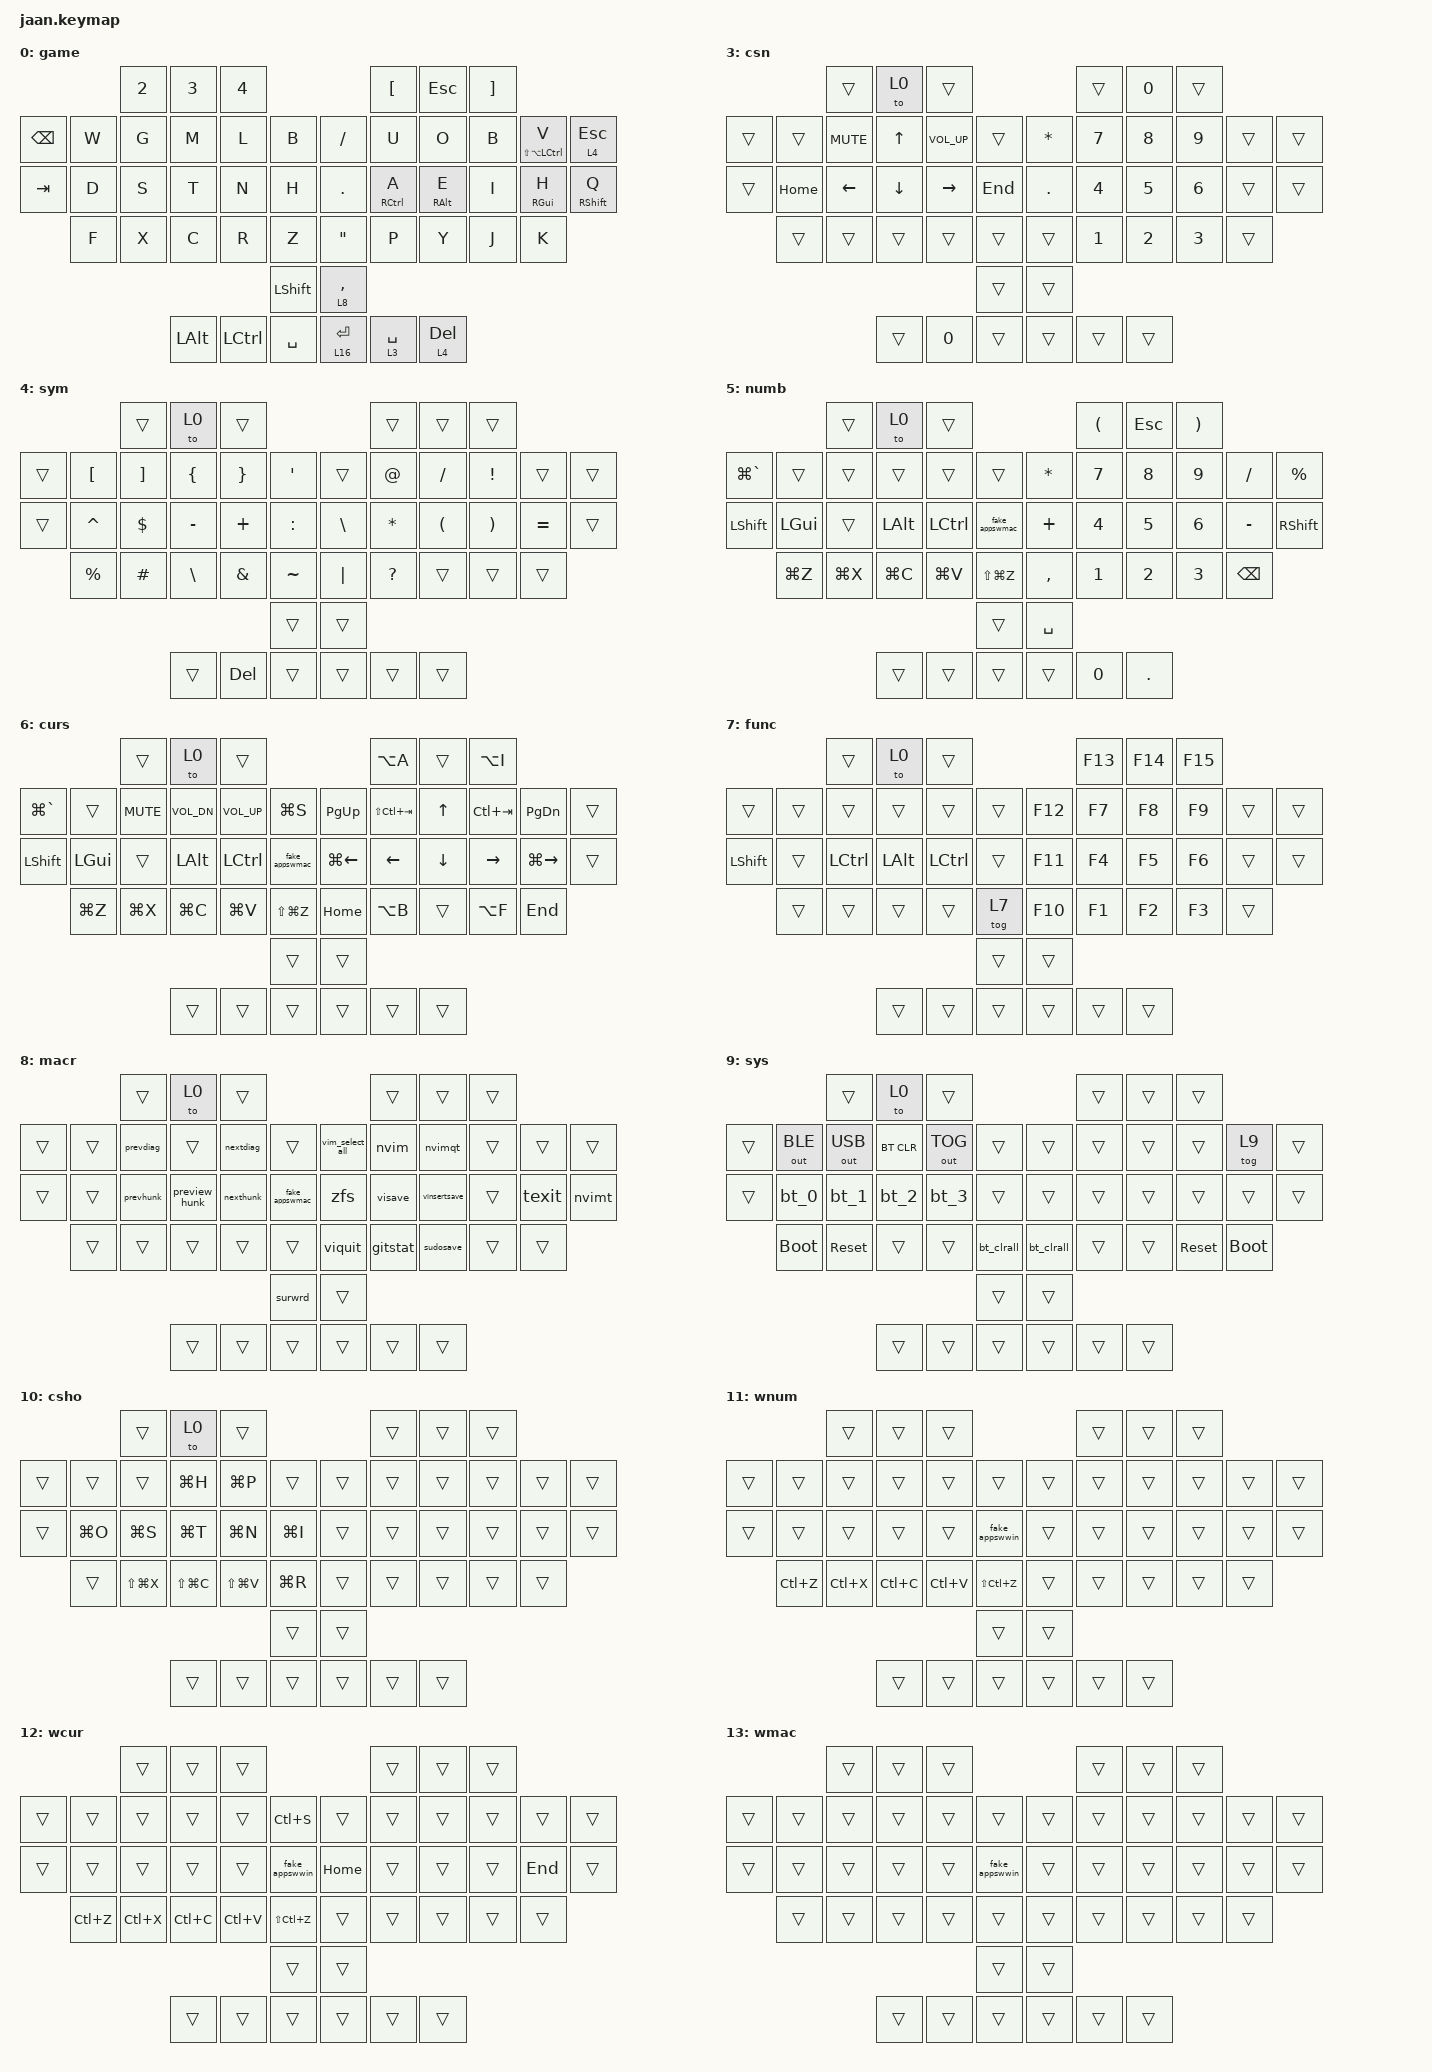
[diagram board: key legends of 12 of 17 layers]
#include <behaviors.dtsi>
#include <dt-bindings/zmk/bt.h>
#include <dt-bindings/zmk/ext_power.h>
#include <dt-bindings/zmk/keys.h>
#include <dt-bindings/zmk/outputs.h>

// #define BASE 0
// #define LOW 1
// #define GAM 2
// #define WIN 3
// #define MIR 4
// #define SYM 5
// #define NUM 6
// #define CUR 7
// #define FUN 8
// #define MCR 9
// #define SYS 10
// #define COMMON_SHORTCUTS 11
// #define THENWIN_NUM 12
// #define THENWIN_CUR 13
// #define THENWIN_MCR 14
// #define THENWIN_SHORTCUTS 15
// #define QWERTY 16
// #define HYPER LG(LC(LA(LSHFT)))
// #define MEH   LC(LA(LSHFT))
// #define HYPF7 &kp LG(LC(LA(LS(F7))))
// #define HYPF8 &kp LG(LC(LA(LS(F8))))
// #define HYPF9 &kp LG(LC(LA(LS(F9))))
// #define ALFRED &kp LG(LC(LA(LS(RBKT))))
// #define TMHP &tmb_hold_preferred // layer-tap for thumb keys with hold-preferred!
// #define TM_MRPH_DEL &tmb_mrph_del

#define COMBO_TIMEOUT_MS 60

// #define THUMB_HOLDING_TYPE "balanced"

// unsupported-behaviors.dtsi is applied at build time by config/real-behaviors.overlay

//
// THUMB_HOLDING_TIME defines how long you need to hold (milliseconds)
// a thumb key to activate a layer.  Shorter holds are treated as taps.
//

#define THUMB_HOLDING_TIME 170

//
// THUMB_REPEAT_DECAY defines how much time you have left (milliseconds)
// after tapping a key to hold it again in order to make it auto-repeat.
//

#define THUMB_REPEAT_DECAY 240 // "tap then hold" for key auto-repeat

// &mt {
//     quick-tap-ms = <100>;
//     global-quick-tap;
//     flavor = "tap-preferred";
//     tapping-term-ms = <170>;
// };
// #include "custom.dtsi"
/* #include "custom-combos.dtsi" */
// #include "custom-behaviors.dtsi"
/* #include "custom-macros.dtsi" */

/ {
    combos {
        compatible = "zmk,combos";

        // R & F

        cmdshift_left {
            bindings = <&kp LG ( LSHIFT )>;
            key-positions = <10 22>;
            timeout-ms = <COMBO_TIMEOUT_MS>;
            layers = <3 4 5 1>;
            slow-release;
        };

        // U & J

        cmdshift_right {
            bindings = <&kp RG ( RSHIFT )>;
            key-positions = <13 25>;
            timeout-ms = <COMBO_TIMEOUT_MS>;
            layers = <3 4 5 1>;
            slow-release;
        };

        // R & F

        ctrlshift_left {
            bindings = <&kp LC ( LSHIFT )>;
            key-positions = <10 22>;
            timeout-ms = <COMBO_TIMEOUT_MS>;
            layers = <2>;
            slow-release;
        };

        // U & J

        ctrlshift_right {
            bindings = <&kp RC ( RSHIFT )>;
            key-positions = <13 25>;
            timeout-ms = <COMBO_TIMEOUT_MS>;
            layers = <2>;
            slow-release;
        };

        // V & B

        combo_quit_macos {
            bindings = <&kp LG ( Q )>;
            key-positions = <33 34>;
            layers = <3 4 5 6 7 8 1>;
            timeout-ms = <COMBO_TIMEOUT_MS>;
            slow-release;
        };

        // G & B

        combo_close_macos {
            bindings = <&kp LG ( W )>;
            key-positions = <23 34>;
            layers = <3 4 5 6 7 8 1>;
            timeout-ms = <COMBO_TIMEOUT_MS>;
            slow-release;
        };

        // G & B

        combo_close_windows {
            bindings = <&kp LC ( W )>;
            key-positions = <34 23>;
            layers = <2>;
            timeout-ms = <COMBO_TIMEOUT_MS>;
            slow-release;
        };

        // T & G

        combo_selectall_macos {
            bindings = <&kp LG ( A )>;
            key-positions = <11 23>;
            layers = <3 4 5 6 7 8 1>;
            timeout-ms = <COMBO_TIMEOUT_MS>;
            slow-release;
        };

        // T & G

        combo_selectall_windows {
            bindings = <&kp LC ( A )>;
            key-positions = <11 23>;
            layers = <2>;
            timeout-ms = <COMBO_TIMEOUT_MS>;
            slow-release;
        };

        // Enter

        combo_enter {
            bindings = <&kp ENTER>;
            key-positions = <32 33>;
            timeout-ms = <COMBO_TIMEOUT_MS>;
            layers = <2 3 4 5 6 7 8 1>;
            slow-release;
        };

        // Space

        combo_space {
            bindings = <&kp SPACE>;
            key-positions = <10 11>;
            timeout-ms = <COMBO_TIMEOUT_MS>;
            layers = <2 3 4 5 6 7 8 1>;
            slow-release;
        };

        // LOW layer

        combo_quit_win {
            bindings = <&kp LA(F4)>;
            key-positions = <33 34>;
            slow-release;
            layers = <2>;
        };
    };

    macros {
        /* tonumword: activate_numword { */
        /*     compatible = "zmk,behavior-macro"; */
        /*     #binding-cells = <0>; */
        /*     wait-ms = <30>; */
        /*     tap-ms = <0>; */
        /*     bindings = <&tog NUM &num_word>; */
        /* }; */

        visave: vim_save_normal {
            compatible = "zmk,behavior-macro";
            #binding-cells = <0>;
            wait-ms = <30>;
            tap-ms = <0>;
            bindings = <&kp LC(LBKT) &kp SEMICOLON &kp W &kp ENTER>;
        };

        nextdiag: next_diag {
            compatible = "zmk,behavior-macro";
            #binding-cells = <0>;
            wait-ms = <30>;
            tap-ms = <0>;
            bindings = <&kp LC(LBKT) &kp RBKT &kp G>;
        };

        prevdiag: prev_diag {
            compatible = "zmk,behavior-macro";
            #binding-cells = <0>;
            wait-ms = <30>;
            tap-ms = <0>;
            bindings = <&kp LC(LBKT) &kp LBKT &kp G>;
        };

        nexthunk: next_hunk {
            compatible = "zmk,behavior-macro";
            #binding-cells = <0>;
            wait-ms = <30>;
            tap-ms = <0>;
            bindings = <&kp LC(LBKT) &kp RBKT &kp C>;
        };

        prevhunk: prev_hunk {
            compatible = "zmk,behavior-macro";
            #binding-cells = <0>;
            wait-ms = <30>;
            tap-ms = <0>;
            bindings = <&kp LC(LBKT) &kp LBKT &kp C>;
        };

        preview_hunk: preview_hunk {
            compatible = "zmk,behavior-macro";
            #binding-cells = <0>;
            wait-ms = <30>;
            tap-ms = <0>;
            bindings = <&kp LC(LBKT) &kp COMMA &kp H &kp P>;
        };

        viquit: vim_write_quit {
            compatible = "zmk,behavior-macro";
            #binding-cells = <0>;
            wait-ms = <30>;
            tap-ms = <0>;
            bindings = <&kp LC(LBKT) &kp SEMICOLON &kp W &kp Q &kp A &kp ENTER>;
        };

        texit: term_exit {
            compatible = "zmk,behavior-macro";
            #binding-cells = <0>;
            wait-ms = <30>;
            tap-ms = <0>;
            bindings = <&kp E &kp X &kp I &kp T &kp ENTER>;
        };

        vinsertsave: vim_insert_save {
            compatible = "zmk,behavior-macro";
            #binding-cells = <0>;
            wait-ms = <30>;
            tap-ms = <0>;
            bindings = <&kp LC(O) &kp SEMICOLON &kp W &kp ENTER>;
        };

        nvimt: nvim_terminal {
            compatible = "zmk,behavior-macro";
            #binding-cells = <0>;
            wait-ms = <30>;
            tap-ms = <0>;
            bindings = <&kp LC(LBKT) &kp SEMICOLON &kp V &kp S &kp ENTER &kp SEMICOLON &kp T &kp E &kp R &kp M &kp ENTER &kp I>;
        };

        nvimqt: nvim_quit {
            compatible = "zmk,behavior-macro";
            #binding-cells = <0>;
            wait-ms = <30>;
            tap-ms = <0>;
            bindings = <&kp LC(LBKT) &kp SEMICOLON &kp Q &kp A &kp ENTER>;
        };

        surwrd: surround_wrd_dqoute {
            compatible = "zmk,behavior-macro";
            #binding-cells = <0>;
            wait-ms = <30>;
            tap-ms = <0>;
            bindings = <&kp V &kp I &kp LS(W) &kp LS(S) &kp DOUBLE_QUOTES>;
        };

        gitstat: git_status {
            compatible = "zmk,behavior-macro";
            #binding-cells = <0>;
            wait-ms = <30>;
            tap-ms = <0>;
            bindings = <&kp G &kp S &kp T &kp ENTER>;
        };

        nvim: run_nvim {
            compatible = "zmk,behavior-macro";
            #binding-cells = <0>;
            wait-ms = <30>;
            tap-ms = <0>;
            bindings = <&kp N &kp V &kp I &kp M &kp ENTER>;
        };

        zfs: zfs_space {
            compatible = "zmk,behavior-macro";
            #binding-cells = <0>;
            wait-ms = <30>;
            tap-ms = <0>;
            bindings = <&kp Z &kp F &kp S &kp SPACE>;
        };

        gif: gif {
            compatible = "zmk,behavior-macro";
            #binding-cells = <0>;
            bindings =
                <&macro_press>,
                <&kp LSHFT>,
                <&macro_tap>,
                <&kp N2>,
                <&macro_release>,
                <&kp LSHFT>,
                <&macro_tap>,
                <&kp G &kp I &kp F>;
        };

        bt_0: bt_profile_macro_0 {
            compatible = "zmk,behavior-macro";
            #binding-cells = <0>;
            bindings = <&out OUT_BLE &bt BT_SEL 0>;
        };

        bt_1: bt_profile_macro_1 {
            compatible = "zmk,behavior-macro";
            #binding-cells = <0>;
            bindings = <&out OUT_BLE &bt BT_SEL 1>;
        };

        bt_2: bt_profile_macro_2 {
            compatible = "zmk,behavior-macro";
            #binding-cells = <0>;
            bindings = <&out OUT_BLE &bt BT_SEL 2>;
        };

        bt_3: bt_profile_macro_3 {
            compatible = "zmk,behavior-macro";
            #binding-cells = <0>;
            bindings = <&out OUT_BLE &bt BT_SEL 3>;
        };

        bt_clrall: bt_clr_all {
            compatible = "zmk,behavior-macro";
            wait-ms = <40>;
            tap-ms = <40>;
            #binding-cells = <0>;
            bindings = <&bt BT_CLR &bt BT_SEL 0 &bt BT_CLR &bt BT_SEL 1 &bt BT_CLR &bt BT_SEL 2 &bt BT_CLR &bt BT_SEL 3 &bt BT_CLR &bt BT_SEL 0>;
        };

        vim_select_all: vim_select_all {
            compatible = "zmk,behavior-macro";
            #binding-cells = <0>;
            bindings =
                <&kp LC(LEFT_BRACKET) &kp G &kp G &kp LS(V)>,
                <&macro_wait_time 300>,
                <&kp LS(G)>;
        };

        sudosave: sudosave {
            compatible = "zmk,behavior-macro";
            #binding-cells = <0>;
            bindings = <&kp LC(LEFT_BRACKET) &kp SEMI &kp W &kp EXCL &kp EXCL>;
        };
    };

    behaviors {
        hl: hrmod_left {
            compatible = "zmk,behavior-hold-tap";
            bindings = <&kp>, <&kp>;

            #binding-cells = <2>;
            quick-tap-ms = <200>;
            require-prior-idle-ms = <150>;
            flavor = "balanced";
            hold-trigger-on-release;
            tapping-term-ms = <240>;
            hold-trigger-key-positions = <3 4 5 12 13 14 15 16 17 24 25 26 27 28 29 35 36 37 38 39 41 46 47 45>;
        };

        hr: hrmod_right {
            compatible = "zmk,behavior-hold-tap";
            bindings = <&kp>, <&kp>;

            #binding-cells = <2>;
            quick-tap-ms = <180>;
            require-prior-idle-ms = <150>;
            flavor = "balanced";
            hold-trigger-on-release;
            tapping-term-ms = <240>;
            hold-trigger-key-positions = <0 1 2 6 7 8 9 10 11 18 19 20 21 22 23 30 31 32 33 34 40 42 43 44>;
        };

        ltr: layer_tap_right {
            compatible = "zmk,behavior-hold-tap";
            bindings = <&mo>, <&kp>;

            #binding-cells = <2>;
            quick-tap-ms = <170>;
            require-prior-idle-ms = <150>;
            flavor = "balanced";
            tapping-term-ms = <170>;
            hold-trigger-key-positions = <30 31 32 33 34>;
        };

        ltl: layer_tap_left {
            compatible = "zmk,behavior-hold-tap";
            bindings = <&mo>, <&kp>;

            #binding-cells = <2>;
            quick-tap-ms = <210>;
            require-prior-idle-ms = <150>;
            flavor = "balanced";
            tapping-term-ms = <170>;
            hold-trigger-key-positions = <36 37 38 27 26 25 13 14 15>;
        };

        tmb: miryoku_thumb_layer {
            compatible = "zmk,behavior-hold-tap";
            bindings = <&mo>, <&kp>;

            #binding-cells = <2>;
            quick-tap-ms = <240>;
            flavor = "balanced";
            tapping-term-ms = <170>;
            retro-tap;
        };

        tmb_hold_preferred: thumb_layer_hold_preferred {
            compatible = "zmk,behavior-hold-tap";
            bindings = <&mo>, <&kp>;

            #binding-cells = <2>;
            quick-tap-ms = <240>;
            flavor = "hold-preferred";
            tapping-term-ms = <170>;
            retro-tap;
        };

        mmt: my_mod_tap {
            compatible = "zmk,behavior-hold-tap";
            bindings = <&kp>, <&kp>;

            #binding-cells = <2>;
            quick-tap-ms = <175>;
            require-prior-idle-ms = <150>;
            flavor = "tap-preferred";
            tapping-term-ms = <280>;
        };

        z_shrt_gr: z_shortcut_cmd_grave {
            compatible = "zmk,behavior-mod-morph";
            bindings = <&ltl 10 Z>, <&kp GRAVE>;

            #binding-cells = <0>;
            mods = <(MOD_LGUI|MOD_RGUI)>;
            keep-mods = <(MOD_LGUI|MOD_RGUI)>;
        };

        dqt_sqt: double_then_single_quote {
            compatible = "zmk,behavior-mod-morph";
            bindings = <&kp DOUBLE_QUOTES>, <&kp SQT>;

            #binding-cells = <0>;
            mods = <(MOD_LSFT|MOD_RSFT)>;
        };

        qtmacnewtab: mac_new_tab {
            compatible = "zmk,behavior-mod-morph";
            bindings = <&dqt_sqt>, <&kp T>;

            #binding-cells = <0>;
            mods = <(MOD_LGUI|MOD_RGUI)>;
            keep-mods = <(MOD_LGUI|MOD_RGUI)>;
        };

        qtwinnewtab: win_new_tab {
            compatible = "zmk,behavior-mod-morph";
            bindings = <&dqt_sqt>, <&kp LC(T)>;

            #binding-cells = <0>;
            mods = <(MOD_LGUI|MOD_RGUI)>;
        };

        shft_bspc: shift_backspace {
            compatible = "zmk,behavior-mod-morph";
            bindings = <&kp BACKSPACE>, <&kp DELETE>;

            #binding-cells = <0>;
            mods = <(MOD_RSFT|MOD_LSFT)>;
        };

        tmb_mrph_del: thumb_morph_delete {
            compatible = "zmk,behavior-hold-tap";
            flavor = "hold-preferred";
            tapping-term-ms = <170>;
            quick-tap-ms = <240>; // enable repeat
            //global-quick-tap; // no typing streak

            retro-tap; // allow slow (hold-like) taps
            #binding-cells = <2>;
            bindings = <&mo>, <&shft_bspc>;

            hold-trigger-key-positions = <30 31 32 33 34 23 11 3 4 5 12 13 14 15 16 17 24 25 26 27 28 29 35 36 37 38 39 41 46 47 18 19 21 22>;
        };

        skq: sticky_key_quick_release {
            compatible = "zmk,behavior-sticky-key";
            bindings = <&kp>;
            #binding-cells = <1>;
            release-after-ms = <1000>;
            quick-release;
            ignore-modifiers;
        };

        smart_shift: smart_shift {
            compatible = "zmk,behavior-mod-morph";
            bindings = <&skq RSHFT>, <&caps_word>;

            #binding-cells = <0>;
            mods = <(MOD_RSFT)>;
        };

        smart_gui: smart_gui_layer_changi {
            compatible = "zmk,behavior-mod-morph";
            bindings = <&skq LGUI>, <&to 7>;

            #binding-cells = <0>;
            mods = <(MOD_LGUI)>;
            keep-mods = <(MOD_LGUI)>;
        };

        fake_bind1: fake_node1_behavior {
            compatible = "zmk,behavior-key-repeat";
            #binding-cells = <0>;
            usage-pages = <HID_USAGE_KEY>;
        };

        fake_appswmac: fake_appswmac_behavior_tristate {
            compatible = "zmk,behavior-key-repeat";
            #binding-cells = <0>;
            usage-pages = <HID_USAGE_KEY>;
        };

        fake_appswwin: fake_appswwin_behavior_tristate {
            compatible = "zmk,behavior-key-repeat";
            #binding-cells = <0>;
            usage-pages = <HID_USAGE_KEY>;
        };

        fake_num_word: fake_num_word_behavior {
            compatible = "zmk,behavior-sticky-key";
            bindings = <&kp>;
            #binding-cells = <1>;
            release-after-ms = <1000>;
        };

        fake_nav_word: fake_nav_word_behavior {
            compatible = "zmk,behavior-sticky-key";
            bindings = <&kp>;
            #binding-cells = <1>;
            release-after-ms = <1000>;
        };

        modtap: mdtap_hold {
            compatible = "zmk,behavior-hold-tap";
            bindings = <&kp>, <&kp>;

            #binding-cells = <2>;
            quick-tap-ms = <240>;
            require-prior-idle-ms = <170>;
            flavor = "hold-preferred";
            tapping-term-ms = <170>;
        };

        dash_bslh_tap: dash_bslh_tap {
            compatible = "zmk,behavior-tap-dance";
            #binding-cells = <0>;
            bindings = <&kp MINUS>, <&kp BSLH>;

            tapping-term-ms = <155>;
        };
    };

    keymap {
        compatible = "zmk,keymap";

        // ▄▄▄▄▄▄▄▄▄▄▄▄▄▄▄▄▄▄▄▄▄▄▄▄▄▄▄▄▄▄▄▄▄▄▄▄▄▄▄▄▄▄▄▄▄▄▄▄▄▄▄▄▄▄▄▄▄▄▄▄▄▄▄▄▄▄▄▄▄▄▄▄▄▄▄▄▄▄▄▄▄▄▄▄▄▄▄▄▄▄▄▄▄▄▄▄▄▄▄▄▄▄▄▄▄▄▄▄▄▄▄▄▄▄▄▄▄▄▄▄▄▄▄▄▄▄▄▄▄▄▄▄▄▄▄▄▄▄▄▄▄▄▄▄▄▄▄▄▄

        game {
            // ┏━━━━━━━━━━━━━━━━━━━━━━━━━━━━━━━━━━━━━━━┓

            display-name = "game";

            // ┗━━━━━━━━━━━━━━━━━━━━━━━━━━━━━━━━━━━━━━━┛
            //              ┏━━━━━━━━━━━┳━━━━━━━━━━━┳━━━━━━━━━━━━━━━━━━┳━━━━━━━━━━━━━━━━━━┳━━━━━━━━━━━━━━━━┓   ┏━━━━━━━━━━━━━━━━━━┳━━━━━━━━━━━━━━━━━━┳━━━━━━━━━━━━━━━━┳━━━━━━━━━━━┳━━━━━━━━━━━┓
            //              ┃     B     ┃     Y     ┃     O            ┃     U            ┃     " (New TAB)┃   ┃      ;           ┃      L           ┃     D          ┃     W     ┃  V (MEH)  ┃
            //              ┣━━━━━━━━━━━╋━━━━━━━━━━━╋━━━━━━━━━━━━━━━━━━╋━━━━━━━━━━━━━━━━━━╋━━━━━━━━━━━━━━━━┫   ┣━━━━━━━━━━━━━━━━━━╋━━━━━━━━━━━━━━━━━━╋━━━━━━━━━━━━━━━━╋━━━━━━━━━━━╋━━━━━━━━━━━┫
            //              ┃ C (LGUI)  ┃     I     ┃     E (ALT)      ┃     A (CTRL)     ┃     , (SHFT)   ┃   ┃      . (SHFT)    ┃      H (CTRL)    ┃     T (ALT)    ┃     S     ┃     N     ┃
            // ┏━━━━━━━━━━━━╋━━━━━━━━━━━╋━━━━━━━━━━━╋━━━━━━━━━━━━━━━━━━╋━━━━━━━━━━━━━━━━━━╋━━━━━━━━━━━━━━━━┫   ┣━━━━━━━━━━━━━━━━━━╋━━━━━━━━━━━━━━━━━━╋━━━━━━━━━━━━━━━━╋━━━━━━━━━━━╋━━━━━━━━━━━╋━━━━━━━━━━━┓
            // ┃Z(SHORTCUTS)┃     J     ┃     X     ┃     K            ┃     G            ┃     / (FUN)    ┃   ┃      _ (HYPER)   ┃      R           ┃     M          ┃     F     ┃     P     ┃     Q     ┃
            // ┗━━━━━━━━━━━━┻━━━━━━━━━━━┻━━━━━━━━━━━╋━━━━━━━━━━━━━━━━━━╋━━━━━━━━━━━━━━━━━━╋━━━━━━━━━━━━━━━━┫   ┣━━━━━━━━━━━━━━━━━━╋━━━━━━━━━━━━━━━━━━╋━━━━━━━━━━━━━━━━╋━━━━━━━━━━━┻━━━━━━━━━━━┻━━━━━━━━━━━┛
            //                                      ┃   ESC (Cursor)   ┃    BSPC (Num)    ┃   TAB (GUI)    ┃   ┃   ENTER(Lower)   ┃    SPC (Macro)   ┃  DEL (Symbols) ┃
            //                                      ┗━━━━━━━━━━━━━━━━━━┻━━━━━━━━━━━━━━━━━━┻━━━━━━━━━━━━━━━━┛   ┗━━━━━━━━━━━━━━━━━━┻━━━━━━━━━━━━━━━━━━┻━━━━━━━━━━━━━━━━┛

            bindings = <
                      &kp NUMBER_2  &kp N3        &kp NUMBER_4                                     &kp LEFT_BRACKET  &kp ESCAPE                    &kp RIGHT_BRACKET
&kp BACKSPACE  &kp W  &kp G         &kp M         &kp L         &kp B           &kp SLASH          &kp U             &kp O                         &kp B              &mmt LS(LA(LCTRL)) V  &lt 4 ESCAPE
&kp TAB        &kp D  &kp S         &kp T         &kp N         &kp H           &kp PERIOD         &hr RCTRL A       &hr RALT E                    &kp I              &hr RGUI H            &hr RSHIFT Q
               &kp F  &kp X         &kp C         &kp R         &kp Z           &kp DOUBLE_QUOTES  &kp P             &kp Y                         &kp J              &kp K
                                                                &kp LEFT_SHIFT  &tmb 8 COMMA
                                    &kp LEFT_ALT  &kp LCTRL     &kp SPACE       &tmb 16 ENTER      &tmb 3 SPACE      &tmb_hold_preferred 4 DELETE
            >;
        };

        mac {
            display-name = "mac";
            bindings = <
                     &kp NUMBER_2  &kp NUMBER_3                  &kp NUMBER_4                                                                   &kp LEFT_BRACKET  &kp LS(LA(LC(LG(RIGHT_BRACKET))))  &kp RIGHT_BRACKET
&ltl 4 GRAVE  &kp W  &kp G         &kp M                         &kp L              &dqt_sqt              &kp SEMICOLON                         &kp U             &kp O                              &kp B              &mmt LS(LA(RCTRL)) V  &trans
&hl LSHFT Z   &kp D  &kp S         &hl LEFT_ALT T                &hl LCTRL N        &kp COMMA             &kp PERIOD                            &hr RCTRL A       &hr RIGHT_ALT E                    &kp I              &hr RIGHT_GUI H       &hr RSHFT Q
              &kp F  &kp X         &kp C                         &kp R              &ltl 7 SLASH          &mmt LS(LA(LC(LEFT_GUI))) UNDERSCORE  &kp P             &kp Y                              &kp J              &kp K
                                                                                    &ltl 10 SPACE         &dash_bslh_tap
                                   &tmb_hold_preferred 6 ESCAPE  &tmb_mrph_del 5 0  &modtap LEFT_GUI TAB  &trans                                &tmb 8 SPACE      &tmb_hold_preferred 4 DELETE
            >;
        };

        windows {
            display-name = "win";
            bindings = <
                          &trans  &trans                     &trans                                                                    &trans        &kp LC(LA(LS(LG(RIGHT_BRACKET))))  &trans
&ltl 4 GRAVE      &trans  &trans  &trans                     &trans             &dqt_sqt              &kp SEMI                         &trans        &trans                             &trans  &trans  &trans
&hl LEFT_SHIFT Z  &trans  &trans  &hl LEFT_ALT T             &hl LCTRL N        &kp COMMA             &trans                           &trans        &trans                             &trans  &trans  &trans
                  &trans  &trans  &trans                     &trans             &ltl 7 FSLH           &mmt LS(LA(LC(LEFT_GUI))) UNDER  &trans        &trans                             &trans  &trans
                                                                                &ltl 10 SPACE         &dash_bslh_tap
                                  &tmb_hold_preferred 6 ESC  &tmb_mrph_del 5 0  &modtap LEFT_GUI TAB  &trans                           &tmb 8 SPACE  &trans
            >;
        };

        cursnum {
            display-name = "csn";
            bindings = <
                  &trans      &to 0     &trans                                &trans  &kp N0  &trans
&trans  &trans    &kp K_MUTE  &kp UP    &kp C_VOLUME_UP  &trans   &kp STAR    &kp N7  &kp N8  &kp N9  &trans  &trans
&trans  &kp HOME  &kp LEFT    &kp DOWN  &kp RIGHT        &kp END  &kp PERIOD  &kp N4  &kp N5  &kp N6  &trans  &trans
        &trans    &trans      &trans    &trans           &trans   &trans      &kp N1  &kp N2  &kp N3  &trans
                                                         &trans   &trans
                              &trans    &kp N0           &trans   &trans      &trans  &trans
            >;
        };

        symbols {
            display-name = "sym";
            bindings = <
                   &trans      &to 0           &trans                                &trans     &trans    &trans
&trans  &kp LBKT   &kp RBKT    &kp LEFT_BRACE  &kp RIGHT_BRACE  &kp SQT    &trans    &kp AT     &kp FSLH  &kp EXCLAMATION  &trans     &trans
&trans  &kp CARET  &kp DOLLAR  &kp MINUS       &kp PLUS         &kp COLON  &kp BSLH  &kp STAR   &kp LPAR  &kp RPAR         &kp EQUAL  &trans
        &kp PRCNT  &kp HASH    &kp BACKSLASH   &kp AMPS         &kp TILDE  &kp PIPE  &kp QMARK  &trans    &trans           &trans
                                                                &trans     &trans
                               &trans          &kp DELETE       &trans     &trans    &trans     &trans
            >;
        };

        numbers {
            display-name = "numb";
            bindings = <
                           &trans     &to 0      &trans                                &kp LEFT_PARENTHESIS  &kp ESCAPE  &kp RIGHT_PARENTHESIS
&kp LG(GRAVE)   &trans     &trans     &trans     &trans     &trans          &kp STAR   &kp N7                &kp N8      &kp N9                 &kp FSLH       &kp PERCENT
&kp LEFT_SHIFT  &kp LGUI   &trans     &kp LALT   &kp LCTRL  &fake_appswmac  &kp PLUS   &kp N4                &kp N5      &kp N6                 &kp MINUS      &kp RIGHT_SHIFT
                &kp LG(Z)  &kp LG(X)  &kp LG(C)  &kp LG(V)  &kp LS(LG(Z))   &kp COMMA  &kp N1                &kp N2      &kp N3                 &kp BACKSPACE
                                                            &trans          &kp SPACE
                                      &trans     &trans     &trans          &trans     &kp N0                &kp DOT
            >;
        };

        cursor {
            display-name = "curs";
            bindings = <
                          &trans      &to 0         &trans                                      &kp LA(A)        &trans    &kp LA(I)
&kp LG(GRAVE)  &trans     &kp K_MUTE  &kp C_VOL_DN  &kp C_VOL_UP  &kp LG(S)       &kp PG_UP     &kp LS(LC(TAB))  &kp UP    &kp LC(TAB)  &kp PG_DN      &trans
&kp LSHIFT     &kp LGUI   &trans      &kp LALT      &kp LCTRL     &fake_appswmac  &kp LG(LEFT)  &kp LEFT         &kp DOWN  &kp RIGHT    &kp LG(RIGHT)  &trans
               &kp LG(Z)  &kp LG(X)   &kp LG(C)     &kp LG(V)     &kp LS(LG(Z))   &kp HOME      &kp LA(B)        &trans    &kp LA(F)    &kp END
                                                                  &trans          &trans
                                      &trans        &trans        &trans          &trans        &trans           &trans
            >;
        };

        functions {
            display-name = "func";
            bindings = <
                        &trans     &to 0     &trans                      &kp F13  &kp F14  &kp F15
&trans          &trans  &trans     &trans    &trans     &trans  &kp F12  &kp F7   &kp F8   &kp F9   &trans  &trans
&kp LEFT_SHIFT  &trans  &kp LCTRL  &kp LALT  &kp LCTRL  &trans  &kp F11  &kp F4   &kp F5   &kp F6   &trans  &trans
                &trans  &trans     &trans    &trans     &tog 7  &kp F10  &kp F1   &kp F2   &kp F3   &trans
                                                        &trans  &trans
                                   &trans    &trans     &trans  &trans   &trans   &trans
            >;
        };

        macroz {
            display-name = "macr";
            bindings = <
                &trans     &to 0          &trans                                      &trans    &trans        &trans
&trans  &trans  &prevdiag  &trans         &nextdiag  &trans          &vim_select_all  &nvim     &nvimqt       &trans  &trans  &trans
&trans  &trans  &prevhunk  &preview_hunk  &nexthunk  &fake_appswmac  &zfs             &visave   &vinsertsave  &trans  &texit  &nvimt
        &trans  &trans     &trans         &trans     &trans          &viquit          &gitstat  &sudosave     &trans  &trans
                                                     &surwrd         &trans
                           &trans         &trans     &trans          &trans           &trans    &trans
            >;

            // label = "git,nvim,zfs macros";
        };

        system {
            display-name = "sys";
            bindings = <
                      &trans        &to 0       &trans                                &trans  &trans  &trans
&trans  &out OUT_BLE  &out OUT_USB  &bt BT_CLR  &out OUT_TOG  &trans      &trans      &trans  &trans  &trans      &tog 9       &trans
&trans  &bt_0         &bt_1         &bt_2       &bt_3         &trans      &trans      &trans  &trans  &trans      &trans       &trans
        &bootloader   &sys_reset    &trans      &trans        &bt_clrall  &bt_clrall  &trans  &trans  &sys_reset  &bootloader
                                                              &trans      &trans
                                    &trans      &trans        &trans      &trans      &trans  &trans
            >;
        };

        common_shortcuts {
            display-name = "csho";
            bindings = <
                   &trans         &to 0          &trans                            &trans  &trans  &trans
&trans  &trans     &trans         &kp LG(H)      &kp LG(P)      &trans     &trans  &trans  &trans  &trans  &trans  &trans
&trans  &kp LG(O)  &kp LG(S)      &kp LG(T)      &kp LG(N)      &kp LG(I)  &trans  &trans  &trans  &trans  &trans  &trans
        &trans     &kp LS(LG(X))  &kp LS(LG(C))  &kp LS(LG(V))  &kp LG(R)  &trans  &trans  &trans  &trans  &trans
                                                                &trans     &trans
                                  &trans         &trans         &trans     &trans  &trans  &trans
            >;
        };

        win_number {
            display-name = "wnum";
            bindings = <
                   &trans     &trans     &trans                             &trans  &trans  &trans
&trans  &trans     &trans     &trans     &trans     &trans          &trans  &trans  &trans  &trans  &trans  &trans
&trans  &trans     &trans     &trans     &trans     &fake_appswwin  &trans  &trans  &trans  &trans  &trans  &trans
        &kp LC(Z)  &kp LC(X)  &kp LC(C)  &kp LC(V)  &kp LS(LC(Z))   &trans  &trans  &trans  &trans  &trans
                                                    &trans          &trans
                              &trans     &trans     &trans          &trans  &trans  &trans
            >;
        };

        win_cursor {
            display-name = "wcur";
            bindings = <
                   &trans     &trans     &trans                               &trans  &trans  &trans
&trans  &trans     &trans     &trans     &trans     &kp LC(S)       &trans    &trans  &trans  &trans  &trans   &trans
&trans  &trans     &trans     &trans     &trans     &fake_appswwin  &kp HOME  &trans  &trans  &trans  &kp END  &trans
        &kp LC(Z)  &kp LC(X)  &kp LC(C)  &kp LC(V)  &kp LS(LC(Z))   &trans    &trans  &trans  &trans  &trans
                                                    &trans          &trans
                              &trans     &trans     &trans          &trans    &trans  &trans
            >;
        };

        win_macro {
            display-name = "wmac";
            bindings = <
                &trans  &trans  &trans                          &trans  &trans  &trans
&trans  &trans  &trans  &trans  &trans  &trans          &trans  &trans  &trans  &trans  &trans  &trans
&trans  &trans  &trans  &trans  &trans  &fake_appswwin  &trans  &trans  &trans  &trans  &trans  &trans
        &trans  &trans  &trans  &trans  &trans          &trans  &trans  &trans  &trans  &trans
                                        &trans          &trans
                        &trans  &trans  &trans          &trans  &trans  &trans
            >;
        };

        win_shortcuts {
            display-name = "wsho";
            bindings = <
                   &trans         &to 0          &trans                            &trans  &trans  &trans
&trans  &trans     &trans         &kp LC(H)      &kp LC(P)      &trans     &trans  &trans  &trans  &trans  &trans  &trans
&trans  &kp LC(O)  &kp LC(S)      &kp LC(T)      &kp LC(N)      &kp LC(I)  &trans  &trans  &trans  &trans  &trans  &trans
        &trans     &kp LS(LC(X))  &kp LS(LC(C))  &kp LS(LC(V))  &kp LC(R)  &trans  &trans  &trans  &trans  &trans
                                                                &trans     &trans
                                  &trans         &trans         &trans     &trans  &trans  &trans
            >;
        };

        qwerty {
            display-name = "qwer";
            bindings = <
               &trans  &trans      &trans                                          &trans       &trans      &trans
&trans  &kp Q  &kp W   &kp E       &kp R        &kp T     &kp Y                    &kp U        &kp I       &kp O    &mmt LS(LA(LCTRL)) P  &trans
&trans  &kp A  &kp S   &hl LALT D  &hl LCTRL F  &kp G     &kp H                    &hr RCTRL J  &hr RALT K  &kp L    &kp SEMI              &trans
        &kp Z  &kp X   &kp C       &kp V        &ltl 7 B  &mmt LS(LA(LC(LGUI))) N  &kp M        &kp COMMA   &kp DOT  &kp FSLH
                                                &trans    &trans
                       &trans      &trans       &trans    &trans                   &trans       &trans
            >;
        };

        layer_toggle {
            display-name = "layer";
            bindings = <
                               &trans     &trans  &trans                  &trans                  &trans                  &to 15
&trans      &to 0              &to 1      &to 2   &to 3   &to 4   &to 5   &to 6                   &to 7                   &to 8                   &to 9   &trans
&z_shrt_gr  &ext_power EP_TOG  &soft_off  &trans  &trans  &trans  &trans  &trans                  &caps_word              &fake_num_word 5        &trans  &trans
            &trans             &trans     &trans  &trans  &to 7   &trans  &kp LS(LA(LC(LG(F7))))  &kp LS(LG(LA(LC(F8))))  &kp LS(LA(LC(LG(F9))))  &trans
                                                          &trans  &trans
                                          &to 6   &to 5   &trans  &trans  &to 8                   &to 4
            >;
        };

        // // ▄▄▄▄▄▄▄▄▄▄▄▄▄▄▄▄▄▄▄▄▄▄▄▄▄▄▄▄▄▄▄▄▄▄▄▄▄▄▄▄▄▄▄▄▄▄▄▄▄▄▄▄▄▄▄▄▄▄▄▄▄▄▄▄▄▄▄▄▄▄▄▄▄▄▄▄▄▄▄▄▄▄▄▄▄▄▄▄▄▄▄▄▄▄▄▄▄▄▄▄▄▄▄▄▄▄▄▄▄▄▄▄▄▄▄▄▄▄▄▄▄▄▄▄▄▄▄▄▄▄▄▄▄▄▄▄▄▄▄▄▄▄▄▄▄▄▄▄▄
        //                 lower_layer {
        // // ┏━━━━━━━━━━━━━━━━━━━━━━━━━━━━━━━━━━━━━━━┓
        // display-name= "LOW"                        ;
        // // ┗━━━━━━━━━━━━━━━━━━━━━━━━━━━━━━━━━━━━━━━┛
        // //             ┏━━━━━━━━━━━┳━━━━━━━━━━━┳━━━━━━━━━━━┳━━━━━━━━━━━┳━━━━━━━━━━━┓   ┏━━━━━━━━━━━┳━━━━━━━━━━━┳━━━━━━━━━━━┳━━━━━━━━━━━┳━━━━━━━━━━━┓
        // //             ┃    L0     ┃    L2     ┃     L3    ┃    L4     ┃    L5     ┃   ┃    L6     ┃    L7     ┃    L8     ┃    L9     ┃    L10    ┃
        // //             ┣━━━━━━━━━━━╋━━━━━━━━━━━╋━━━━━━━━━━━╋━━━━━━━━━━━╋━━━━━━━━━━━┫   ┣━━━━━━━━━━━╋━━━━━━━━━━━╋━━━━━━━━━━━╋━━━━━━━━━━━╋━━━━━━━━━━━┫
        // //             ┃           ┃           ┃           ┃           ┃           ┃   ┃           ┃  Alfred   ┃ &capswrd  ┃ &num_word ┃           ┃
        // // ┏━━━━━━━━━━━╋━━━━━━━━━━━╋━━━━━━━━━━━╋━━━━━━━━━━━╋━━━━━━━━━━━╋━━━━━━━━━━━┫   ┣━━━━━━━━━━━╋━━━━━━━━━━━╋━━━━━━━━━━━╋━━━━━━━━━━━╋━━━━━━━━━━━╋━━━━━━━━━━━┓
        // // ┃   L0      ┃           ┃           ┃           ┃           ┃    FUN    ┃   ┃           ┃ HYP_F7    ┃ HYP_F8    ┃  HYP_F9   ┃           ┃           ┃
        // // ┗━━━━━━━━━━━┻━━━━━━━━━━━┻━━━━━━━━━━━╋━━━━━━━━━━━╋━━━━━━━━━━━╋━━━━━━━━━━━┫   ┣━━━━━━━━━━━╋━━━━━━━━━━━╋━━━━━━━━━━━╋━━━━━━━━━━━┻━━━━━━━━━━━┻━━━━━━━━━━━┛
        // //                                     ┃    CUR    ┃    NUM    ┃           ┃   ┃           ┃   Macro   ┃    SYM    ┃
        // //                                     ┗━━━━━━━━━━━┻━━━━━━━━━━━┻━━━━━━━━━━━┛   ┗━━━━━━━━━━━┻━━━━━━━━━━━┻━━━━━━━━━━━┛
        //  bindings = <
        // // ╷           ╷           ╷           ╷           ╷           ╷           ╷   ╷           ╷           ╷           ╷           ╷           ╷           ╷
        //                 &to 0       &to 2       &to 3       &to 4       &to 5           &to 6       &to 7       &to 8       &to 9       &tog 10
        //                 &trans      &trans      &trans      &trans      &trans          &trans      ALFRED      &caps_word  &num_word   &trans
        //     &to BASE    &trans      &trans      &trans      &trans      &to FUN         &trans      HYPF7       HYPF8       HYPF9       &trans      &trans
        //                                         &to CUR     &to NUM     &trans          &trans      &to MCR     &to SYM
        //                         >;
        //                 };
        // // ▄▄▄▄▄▄▄▄▄▄▄▄▄▄▄▄▄▄▄▄▄▄▄▄▄▄▄▄▄▄▄▄▄▄▄▄▄▄▄▄▄▄▄▄▄▄▄▄▄▄▄▄▄▄▄▄▄▄▄▄▄▄▄▄▄▄▄▄▄▄▄▄▄▄▄▄▄▄▄▄▄▄▄▄▄▄▄▄▄▄▄▄▄▄▄▄▄▄▄▄▄▄▄▄▄▄▄▄▄▄▄▄▄▄▄▄▄▄▄▄▄▄▄▄▄▄▄▄▄▄▄▄▄▄▄▄▄▄▄▄▄▄▄▄▄▄▄▄▄
        //                 game_layer {
        // // ┏━━━━━━━━━━━━━━━━━━━━━━━━━━━━━━━━━━━━━━━┓
        // display-name= "GAM"                        ;
        // // ┗━━━━━━━━━━━━━━━━━━━━━━━━━━━━━━━━━━━━━━━┛
        // //           ┏━━━━━━━━━━━┳━━━━━━━━━━━┳━━━━━━━━━━━┳━━━━━━━━━━━┳━━━━━━━━━━━┓   ┏━━━━━━━━━━━┳━━━━━━━━━━━┳━━━━━━━━━━━┳━━━━━━━━━━━┳━━━━━━━━━━━┓
        // //           ┃           ┃           ┃           ┃           ┃     B     ┃   ┃           ┃           ┃           ┃           ┃           ┃
        // //           ┣━━━━━━━━━━━╋━━━━━━━━━━━╋━━━━━━━━━━━╋━━━━━━━━━━━╋━━━━━━━━━━━┫   ┣━━━━━━━━━━━╋━━━━━━━━━━━╋━━━━━━━━━━━╋━━━━━━━━━━━╋━━━━━━━━━━━┫
        // //           ┃     D     ┃           ┃     T     ┃     N     ┃     H     ┃   ┃           ┃           ┃           ┃           ┃           ┃
        // // ┏━━━━━━━━━╋━━━━━━━━━━━╋━━━━━━━━━━━╋━━━━━━━━━━━╋━━━━━━━━━━━╋━━━━━━━━━━━┫   ┣━━━━━━━━━━━╋━━━━━━━━━━━╋━━━━━━━━━━━╋━━━━━━━━━━━╋━━━━━━━━━━━╋━━━━━━━━━━━┓
        // // ┃TAB/BKSP ┃           ┃           ┃           ┃           ┃     Z     ┃   ┃    ESC    ┃           ┃           ┃           ┃           ┃  Q (NUM)  ┃
        // // ┗━━━━━━━━━┻━━━━━━━━━━━┻━━━━━━━━━━━╋━━━━━━━━━━━╋━━━━━━━━━━━╋━━━━━━━━━━━┫   ┣━━━━━━━━━━━╋━━━━━━━━━━━╋━━━━━━━━━━━╋━━━━━━━━━━━┻━━━━━━━━━━━┻━━━━━━━━━━━┛
        // //                                   ┃   LALT    ┃   LCTRL   ┃   SPACE   ┃   ┃           ┃           ┃           ┃
        // //                                   ┗━━━━━━━━━━━┻━━━━━━━━━━━┻━━━━━━━━━━━┛   ┗━━━━━━━━━━━┻━━━━━━━━━━━┻━━━━━━━━━━━┛
        //  bindings = <
        // // ╷         ╷           ╷           ╷           ╷           ╷           ╷   ╷           ╷           ╷           ╷           ╷           ╷           ╷
        //                &trans     &trans      &trans      &trans      &kp B           &trans      &trans      &trans      &trans      &trans
        //                &kp D      &trans      &kp T       &kp N       &kp H           &trans      &trans      &trans      &trans      &trans
        //     &tab_bksp  &trans     &trans      &trans      &trans      &kp Z           &kp ESC     &trans      &trans      &trans      &trans      &ltl NUM Q
        //                                       &kp LALT    &kp LCTRL   &kp SPACE       &trans      &trans      &trans
        //                         >;
        //                 };
        // // ▄▄▄▄▄▄▄▄▄▄▄▄▄▄▄▄▄▄▄▄▄▄▄▄▄▄▄▄▄▄▄▄▄▄▄▄▄▄▄▄▄▄▄▄▄▄▄▄▄▄▄▄▄▄▄▄▄▄▄▄▄▄▄▄▄▄▄▄▄▄▄▄▄▄▄▄▄▄▄▄▄▄▄▄▄▄▄▄▄▄▄▄▄▄▄▄▄▄▄▄▄▄▄▄▄▄▄▄▄▄▄▄▄▄▄▄▄▄▄▄▄▄▄▄▄▄▄▄▄▄▄▄▄▄▄▄▄▄▄▄▄▄▄▄▄▄▄▄▄
        //                 windows_layer {
        // // ┏━━━━━━━━━━━━━━━━━━━━━━━━━━━━━━━━━━━━━━━┓
        // display-name= "WIN"                        ;
        // // ┗━━━━━━━━━━━━━━━━━━━━━━━━━━━━━━━━━━━━━━━┛
        // //             ┏━━━━━━━━━━━┳━━━━━━━━━━━┳━━━━━━━━━━━┳━━━━━━━━━━━┳━━━━━━━━━━━┓   ┏━━━━━━━━━━━┳━━━━━━━━━━━┳━━━━━━━━━━━┳━━━━━━━━━━━┳━━━━━━━━━━━┓
        // //             ┃           ┃           ┃           ┃           ┃ NEW TAB   ┃   ┃           ┃           ┃           ┃           ┃           ┃
        // //             ┣━━━━━━━━━━━╋━━━━━━━━━━━╋━━━━━━━━━━━╋━━━━━━━━━━━╋━━━━━━━━━━━┫   ┣━━━━━━━━━━━╋━━━━━━━━━━━╋━━━━━━━━━━━╋━━━━━━━━━━━╋━━━━━━━━━━━┫
        // //             ┃           ┃           ┃           ┃           ┃           ┃   ┃           ┃           ┃           ┃           ┃           ┃
        // // ┏━━━━━━━━━━━╋━━━━━━━━━━━╋━━━━━━━━━━━╋━━━━━━━━━━━╋━━━━━━━━━━━╋━━━━━━━━━━━┫   ┣━━━━━━━━━━━╋━━━━━━━━━━━╋━━━━━━━━━━━╋━━━━━━━━━━━╋━━━━━━━━━━━╋━━━━━━━━━━━┓
        // // ┃           ┃           ┃           ┃           ┃           ┃           ┃   ┃           ┃           ┃           ┃           ┃           ┃           ┃
        // // ┗━━━━━━━━━━━┻━━━━━━━━━━━┻━━━━━━━━━━━╋━━━━━━━━━━━╋━━━━━━━━━━━╋━━━━━━━━━━━┫   ┣━━━━━━━━━━━╋━━━━━━━━━━━╋━━━━━━━━━━━╋━━━━━━━━━━━┻━━━━━━━━━━━┻━━━━━━━━━━━┛
        // //                                     ┃           ┃           ┃           ┃   ┃           ┃           ┃           ┃
        // //                                     ┗━━━━━━━━━━━┻━━━━━━━━━━━┻━━━━━━━━━━━┛   ┗━━━━━━━━━━━┻━━━━━━━━━━━┻━━━━━━━━━━━┛
        //  bindings = <
        // // ╷           ╷           ╷           ╷           ╷           ╷           ╷   ╷           ╷           ╷           ╷           ╷           ╷           ╷
        //                 &trans       &trans       &trans       &trans   &qtwinnewtab    &trans       &trans      &trans      &trans      &trans
        //                 &trans       &trans       &trans       &trans   &trans          &trans       &trans      &trans      &trans      &trans
        //     &trans      &trans       &trans       &trans       &trans   &trans          &trans       &trans      &trans      &trans      &trans      &trans
        //                                           &trans       &trans   &trans          &trans       &trans      &trans
        //                         >;
        //                 };
        // // ▄▄▄▄▄▄▄▄▄▄▄▄▄▄▄▄▄▄▄▄▄▄▄▄▄▄▄▄▄▄▄▄▄▄▄▄▄▄▄▄▄▄▄▄▄▄▄▄▄▄▄▄▄▄▄▄▄▄▄▄▄▄▄▄▄▄▄▄▄▄▄▄▄▄▄▄▄▄▄▄▄▄▄▄▄▄▄▄▄▄▄▄▄▄▄▄▄▄▄▄▄▄▄▄▄▄▄▄▄▄▄▄▄▄▄▄▄▄▄▄▄▄▄▄▄▄▄▄▄▄▄▄▄▄▄▄▄▄▄▄▄▄▄▄▄▄▄▄▄
        //                 mirror_layer {
        // // ┏━━━━━━━━━━━━━━━━━━━━━━━━━━━━━━━━━━━━━━━┓
        // display-name= "MIR"                        ;
        // // ┗━━━━━━━━━━━━━━━━━━━━━━━━━━━━━━━━━━━━━━━┛
        // //             ┏━━━━━━━━━━━┳━━━━━━━━━━━┳━━━━━━━━━━━┳━━━━━━━━━━━┳━━━━━━━━━━━┓   ┏━━━━━━━━━━━┳━━━━━━━━━━━┳━━━━━━━━━━━┳━━━━━━━━━━━┳━━━━━━━━━━━┓
        // //             ┃ NEXT FILE ┃ MARK IN   ┃ ROTATE    ┃ MARK OUT  ┃ SHOW SNAP ┃   ┃           ┃           ┃           ┃           ┃           ┃
        // //             ┣━━━━━━━━━━━╋━━━━━━━━━━━╋━━━━━━━━━━━╋━━━━━━━━━━━╋━━━━━━━━━━━┫   ┣━━━━━━━━━━━╋━━━━━━━━━━━╋━━━━━━━━━━━╋━━━━━━━━━━━╋━━━━━━━━━━━┫
        // //             ┃ TVP II    ┃ LEFT      ┃ PAN       ┃ RIGHT     ┃ PLAY/FLIP ┃   ┃           ┃           ┃           ┃           ┃           ┃
        // // ┏━━━━━━━━━━━╋━━━━━━━━━━━╋━━━━━━━━━━━╋━━━━━━━━━━━╋━━━━━━━━━━━╋━━━━━━━━━━━┫   ┣━━━━━━━━━━━╋━━━━━━━━━━━╋━━━━━━━━━━━╋━━━━━━━━━━━╋━━━━━━━━━━━╋━━━━━━━━━━━┓
        // // ┃ TO BASE   ┃ SHIFT     ┃ COPY      ┃ DELETE    ┃ PASTE     ┃ IMG MARK  ┃   ┃           ┃           ┃           ┃           ┃           ┃           ┃
        // // ┗━━━━━━━━━━━┻━━━━━━━━━━━┻━━━━━━━━━━━╋━━━━━━━━━━━╋━━━━━━━━━━━╋━━━━━━━━━━━┫   ┣━━━━━━━━━━━╋━━━━━━━━━━━╋━━━━━━━━━━━╋━━━━━━━━━━━┻━━━━━━━━━━━┻━━━━━━━━━━━┛
        // //                                     ┃           ┃ UNDO/SAVE ┃  SEL/MOV  ┃   ┃           ┃           ┃           ┃
        // //                                     ┗━━━━━━━━━━━┻━━━━━━━━━━━┻━━━━━━━━━━━┛   ┗━━━━━━━━━━━┻━━━━━━━━━━━┻━━━━━━━━━━━┛
        //  bindings = <
        // // ╷           ╷           ╷           ╷           ╷           ╷           ╷   ╷           ╷           ╷           ╷           ╷           ╷           ╷
        //                 &kp Q       &kp W       &kp E       &kp R       &kp T           &kp Y        &kp U        &kp I        &kp O     &kp P
        //                 &kp A       &kp S       &kp D       &kp F       &kp G           &kp H        &kp J        &kp K        &kp L     &kp SEMI
        //     &to BASE    &kp Z       &kp X       &kp C       &kp V       &kp B           &kp N        &kp M        &kp COMMA    &kp DOT   &kp FSLH    &kp SQT
        //                                         &trans      &trans      &trans          &trans       &trans       &trans
        //                         >;
        //                 };
        // // ▄▄▄▄▄▄▄▄▄▄▄▄▄▄▄▄▄▄▄▄▄▄▄▄▄▄▄▄▄▄▄▄▄▄▄▄▄▄▄▄▄▄▄▄▄▄▄▄▄▄▄▄▄▄▄▄▄▄▄▄▄▄▄▄▄▄▄▄▄▄▄▄▄▄▄▄▄▄▄▄▄▄▄▄▄▄▄▄▄▄▄▄▄▄▄▄▄▄▄▄▄▄▄▄▄▄▄▄▄▄▄▄▄▄▄▄▄▄▄▄▄▄▄▄▄▄▄▄▄▄▄▄▄▄▄▄▄▄▄▄▄▄▄▄▄▄▄▄▄
        //                 symbols_layer {
        // // ┏━━━━━━━━━━━━━━━━━━━━━━━━━━━━━━━━━━━━━━━┓
        // display-name= "SYM"                        ;
        // // ┗━━━━━━━━━━━━━━━━━━━━━━━━━━━━━━━━━━━━━━━┛
        // //             ┏━━━━━━━━━━━┳━━━━━━━━━━━┳━━━━━━━━━━━┳━━━━━━━━━━━┳━━━━━━━━━━━┓   ┏━━━━━━━━━━━┳━━━━━━━━━━━┳━━━━━━━━━━━┳━━━━━━━━━━━┳━━━━━━━━━━━┓
        // //             ┃     [     ┃     ]     ┃     {     ┃     }     ┃     '     ┃   ┃     `     ┃     @     ┃     /     ┃     !     ┃           ┃
        // //             ┣━━━━━━━━━━━╋━━━━━━━━━━━╋━━━━━━━━━━━╋━━━━━━━━━━━╋━━━━━━━━━━━┫   ┣━━━━━━━━━━━╋━━━━━━━━━━━╋━━━━━━━━━━━╋━━━━━━━━━━━╋━━━━━━━━━━━┫
        // //             ┃     ^     ┃     $     ┃      -    ┃     +     ┃     :     ┃   ┃     \     ┃     *     ┃     (     ┃     )     ┃     =     ┃
        // // ┏━━━━━━━━━━━╋━━━━━━━━━━━╋━━━━━━━━━━━╋━━━━━━━━━━━╋━━━━━━━━━━━╋━━━━━━━━━━━┫   ┣━━━━━━━━━━━╋━━━━━━━━━━━╋━━━━━━━━━━━╋━━━━━━━━━━━╋━━━━━━━━━━━╋━━━━━━━━━━━┓
        // // ┃ TO BASE   ┃     %     ┃     #     ┃      _    ┃     &     ┃     ~     ┃   ┃     |     ┃     ?     ┃     <     ┃     >     ┃           ┃           ┃
        // // ┗━━━━━━━━━━━┻━━━━━━━━━━━┻━━━━━━━━━━━╋━━━━━━━━━━━╋━━━━━━━━━━━╋━━━━━━━━━━━┫   ┣━━━━━━━━━━━╋━━━━━━━━━━━╋━━━━━━━━━━━╋━━━━━━━━━━━┻━━━━━━━━━━━┻━━━━━━━━━━━┛
        // //                                     ┃           ┃           ┃           ┃   ┃           ┃           ┃           ┃
        // //                                     ┗━━━━━━━━━━━┻━━━━━━━━━━━┻━━━━━━━━━━━┛   ┗━━━━━━━━━━━┻━━━━━━━━━━━┻━━━━━━━━━━━┛
        //  bindings = <
        // // ╷           ╷           ╷           ╷           ╷           ╷           ╷   ╷           ╷           ╷           ╷           ╷           ╷           ╷
        //                 &kp LBKT    &kp RBKT    &kp LBRC    &kp RBRC    &kp SQT         &kp GRAVE    &kp AT      &kp FSLH     &kp EXCL   &trans
        //                 &kp CARET   &kp DLLR    &kp MINUS   &kp PLUS    &kp COLON       &kp BSLH     &kp ASTRK   &kp LPAR     &kp RPAR   &kp EQUAL
        //     &to BASE    &kp PRCNT   &kp HASH    &kp UNDER   &kp AMPS    &kp TILDE       &kp PIPE     &kp QMARK   &kp LT       &kp GT     &trans     &trans
        //                                         &trans      &trans      &trans          &trans       &trans      &trans
        //                         >;
        //                 };
        // // ▄▄▄▄▄▄▄▄▄▄▄▄▄▄▄▄▄▄▄▄▄▄▄▄▄▄▄▄▄▄▄▄▄▄▄▄▄▄▄▄▄▄▄▄▄▄▄▄▄▄▄▄▄▄▄▄▄▄▄▄▄▄▄▄▄▄▄▄▄▄▄▄▄▄▄▄▄▄▄▄▄▄▄▄▄▄▄▄▄▄▄▄▄▄▄▄▄▄▄▄▄▄▄▄▄▄▄▄▄▄▄▄▄▄▄▄▄▄▄▄▄▄▄▄▄▄▄▄▄▄▄▄▄▄▄▄▄▄▄▄▄▄▄▄▄▄▄▄▄
        //                 numbers_layer {
        // // ┏━━━━━━━━━━━━━━━━━━━━━━━━━━━━━━━━━━━━━━━┓
        // display-name= "NUM"                        ;
        // // ┗━━━━━━━━━━━━━━━━━━━━━━━━━━━━━━━━━━━━━━━┛
        // //             ┏━━━━━━━━━━━━┳━━━━━━━━━━━━┳━━━━━━━━━━━━━┳━━━━━━━━━━━━━┳━━━━━━━━━━━┓     ┏━━━━━━━━━━━┳━━━━━━━━━━━┳━━━━━━━━━━━┳━━━━━━━━━━━┳━━━━━━━━━━━━┓
        // //             ┃            ┃            ┃             ┃             ┃    SAVE   ┃     ┃     *     ┃     7     ┃     8     ┃     9     ┃     /      ┃
        // //             ┣━━━━━━━━━━━━╋━━━━━━━━━━━━╋━━━━━━━━━━━━━╋━━━━━━━━━━━━━╋━━━━━━━━━━━┫     ┣━━━━━━━━━━━╋━━━━━━━━━━━╋━━━━━━━━━━━╋━━━━━━━━━━━╋━━━━━━━━━━━━┫
        // //             ┃  LGUI      ┃   LSHFT    ┃    LALT     ┃    LCTRL    ┃  CMD+TAB  ┃     ┃     +     ┃     4     ┃     5     ┃     6     ┃     -      ┃
        // // ┏━━━━━━━━━━━╋━━━━━━━━━━━━╋━━━━━━━━━━━━╋━━━━━━━━━━━━━╋━━━━━━━━━━━━━╋━━━━━━━━━━━┫     ┣━━━━━━━━━━━╋━━━━━━━━━━━╋━━━━━━━━━━━╋━━━━━━━━━━━╋━━━━━━━━━━━━╋━━━━━━━━━┓
        // // ┃  TO BASE  ┃  UNDO      ┃    CUT     ┃    COPY     ┃    PASTE    ┃    REDO   ┃     ┃     ,     ┃     1     ┃     2     ┃     3     ┃     =      ┃  BKSPC  ┃
        // // ┗━━━━━━━━━━━┻━━━━━━━━━━━━┻━━━━━━━━━━━━╋━━━━━━━━━━━━━╋━━━━━━━━━━━━━╋━━━━━━━━━━━┫     ┣━━━━━━━━━━━╋━━━━━━━━━━━╋━━━━━━━━━━━╋━━━━━━━━━━━┻━━━━━━━━━━━━┻━━━━━━━━━┛
        // //                                       ┃             ┃             ┃   CMD+O   ┃     ┃    SPC    ┃     0     ┃    DOT    ┃
        // //                                       ┗━━━━━━━━━━━━━┻━━━━━━━━━━━━━┻━━━━━━━━━━━┛     ┗━━━━━━━━━━━┻━━━━━━━━━━━┻━━━━━━━━━━━┛
        //  bindings = <
        // // ╷           ╷            ╷            ╷             ╷             ╷            ╷    ╷           ╷           ╷           ╷           ╷            ╷         ╷
        //                 &trans       &trans       &trans        &trans        &kp LG(S)         &kp STAR    &kp N7      &kp N8      &kp N9      &kp FSLH
        //                 &kp LGUI     &kp LSHFT    &kp LALT      &kp LCTRL     &appswmac         &kp PLUS    &kp N4      &kp N5      &kp N6      &kp MINUS
        //     &to BASE    &kp LG(Z)    &kp LG(X)    &kp LG(C)     &kp LG(V)     &kp LS(LG(Z))     &kp COMMA   &kp N1      &kp N2      &kp N3      &kp EQUAL    &kp BSPC
        //                                           &trans        &trans        &kp LG(O)         &kp SPACE   &kp N0      &kp DOT
        //                         >;
        //                 };
        // // ▄▄▄▄▄▄▄▄▄▄▄▄▄▄▄▄▄▄▄▄▄▄▄▄▄▄▄▄▄▄▄▄▄▄▄▄▄▄▄▄▄▄▄▄▄▄▄▄▄▄▄▄▄▄▄▄▄▄▄▄▄▄▄▄▄▄▄▄▄▄▄▄▄▄▄▄▄▄▄▄▄▄▄▄▄▄▄▄▄▄▄▄▄▄▄▄▄▄▄▄▄▄▄▄▄▄▄▄▄▄▄▄▄▄▄▄▄▄▄▄▄▄▄▄▄▄▄▄▄▄▄▄▄▄▄▄▄▄▄▄▄▄▄▄▄▄▄▄▄
        //                 cursor_layer {
        // // ┏━━━━━━━━━━━━━━━━━━━━━━━━━━━━━━━━━━━━━━━┓
        // display-name= "CUR"                        ;
        // // ┗━━━━━━━━━━━━━━━━━━━━━━━━━━━━━━━━━━━━━━━┛
        // //             ┏━━━━━━━━━━━┳━━━━━━━━━━━━┳━━━━━━━━━━━━┳━━━━━━━━━━━━━┳━━━━━━━━━━━━━━┓    ┏━━━━━━━━━━━━━━┳━━━━━━━━━━━━━━━━┳━━━━━━━━━━━┳━━━━━━━━━━━━━━┳━━━━━━━━━━━━━━━┓
        // //             ┃           ┃    MUTE    ┃   VOL DN   ┃   VOL UP    ┃     SAVE     ┃    ┃     PG UP    ┃   PREV TAB     ┃    UP     ┃   NEXT TAB   ┃    PG DOWN    ┃
        // //             ┣━━━━━━━━━━━╋━━━━━━━━━━━━╋━━━━━━━━━━━━╋━━━━━━━━━━━━━╋━━━━━━━━━━━━━━┫    ┣━━━━━━━━━━━━━━╋━━━━━━━━━━━━━━━━╋━━━━━━━━━━━╋━━━━━━━━━━━━━━╋━━━━━━━━━━━━━━━┫
        // //             ┃    LGUI   ┃   LSHFT    ┃    LALT    ┃    LCTRL    ┃   CMD+TAB    ┃    ┃      bol     ┃     LEFT       ┃   DOWN    ┃    RIGHT     ┃     eol       ┃
        // // ┏━━━━━━━━━━━╋━━━━━━━━━━━╋━━━━━━━━━━━━╋━━━━━━━━━━━━╋━━━━━━━━━━━━━╋━━━━━━━━━━━━━━┫    ┣━━━━━━━━━━━━━━╋━━━━━━━━━━━━━━━━╋━━━━━━━━━━━╋━━━━━━━━━━━━━━╋━━━━━━━━━━━━━━━╋━━━━━━━━━━━┓
        // // ┃  TO BASE  ┃   UNDO    ┃    CUT     ┃    COPY    ┃    PASTE    ┃     REDO     ┃    ┃              ┃     ALT+B      ┃           ┃    ALT+F     ┃               ┃  TO BASE  ┃
        // // ┗━━━━━━━━━━━┻━━━━━━━━━━━┻━━━━━━━━━━━━╋━━━━━━━━━━━━╋━━━━━━━━━━━━━╋━━━━━━━━━━━━━━┫    ┣━━━━━━━━━━━━━━╋━━━━━━━━━━━━━━━━╋━━━━━━━━━━━╋━━━━━━━━━━━━━━┻━━━━━━━━━━━━━━━┻━━━━━━━━━━━┛
        // //                                      ┃            ┃             ┃              ┃    ┃              ┃                ┃           ┃
        // //                                      ┗━━━━━━━━━━━━┻━━━━━━━━━━━━━┻━━━━━━━━━━━━━━┛    ┗━━━━━━━━━━━━━━┻━━━━━━━━━━━━━━━━┻━━━━━━━━━━━┛
        //  bindings = <
        //  //╷           ╷           ╷           ╷             ╷             ╷              ╷    ╷              ╷                ╷           ╷              ╷               ╷           ╷
        //                 &trans      &kp C_MUTE  &kp C_VOL_DN  &kp C_VOL_UP  &kp LG(S)           &kp PG_UP      &kp LS(LC(TAB))  &kp UP      &kp LC(TAB)    &kp PG_DN
        //                 &kp LGUI    &kp LSHFT   &kp LALT      &kp LCTRL     &appswmac           &kp LG(LEFT)   &kp LEFT         &kp DOWN    &kp RIGHT      &kp LG(RIGHT)
        //     &to BASE    &kp LG(Z)   &kp LG(X)   &kp LG(C)     &kp LG(V)     &kp LS(LG(Z))       &trans         &kp LA(B)        &trans      &kp LA(F)      &trans          &to BASE
        //                                         &trans        &trans        &trans              &trans         &trans           &trans
        //                          >;
        //                 };
        // // ▄▄▄▄▄▄▄▄▄▄▄▄▄▄▄▄▄▄▄▄▄▄▄▄▄▄▄▄▄▄▄▄▄▄▄▄▄▄▄▄▄▄▄▄▄▄▄▄▄▄▄▄▄▄▄▄▄▄▄▄▄▄▄▄▄▄▄▄▄▄▄▄▄▄▄▄▄▄▄▄▄▄▄▄▄▄▄▄▄▄▄▄▄▄▄▄▄▄▄▄▄▄▄▄▄▄▄▄▄▄▄▄▄▄▄▄▄▄▄▄▄▄▄▄▄▄▄▄▄▄▄▄▄▄▄▄▄▄▄▄▄▄▄▄▄▄▄▄▄
        //                 functionkeys_layer {
        // // ┏━━━━━━━━━━━━━━━━━━━━━━━━━━━━━━━━━━━━━━━┓
        // display-name= "FUN"                        ;
        // // ┗━━━━━━━━━━━━━━━━━━━━━━━━━━━━━━━━━━━━━━━┛
        // //             ┏━━━━━━━━━━━┳━━━━━━━━━━━━━┳━━━━━━━━━━━━━┳━━━━━━━━━━━━━┳━━━━━━━━━━━┓        ┏━━━━━━━━━━━┳━━━━━━━━━━━┳━━━━━━━━━━━┳━━━━━━━━━━━┳━━━━━━━━━━━┓
        // //             ┃           ┃    MUTE     ┃    VOL DN   ┃    VOL UP   ┃           ┃        ┃    F12    ┃    F7     ┃    F8     ┃    F9     ┃           ┃
        // //             ┣━━━━━━━━━━━╋━━━━━━━━━━━━━╋━━━━━━━━━━━━━╋━━━━━━━━━━━━━╋━━━━━━━━━━━┫        ┣━━━━━━━━━━━╋━━━━━━━━━━━╋━━━━━━━━━━━╋━━━━━━━━━━━╋━━━━━━━━━━━┫
        // //             ┃    LGUI   ┃   LSHFT     ┃    LALT     ┃    LCTRL    ┃           ┃        ┃    F11    ┃    F4     ┃    F5     ┃    F6     ┃           ┃
        // // ┏━━━━━━━━━━━╋━━━━━━━━━━━╋━━━━━━━━━━━━━╋━━━━━━━━━━━━━╋━━━━━━━━━━━━━╋━━━━━━━━━━━┫        ┣━━━━━━━━━━━╋━━━━━━━━━━━╋━━━━━━━━━━━╋━━━━━━━━━━━╋━━━━━━━━━━━╋━━━━━━━━━━━┓
        // // ┃  TO BASE  ┃           ┃             ┃             ┃             ┃  TOG FUN  ┃        ┃    F10    ┃    F1     ┃    F2     ┃    F3     ┃           ┃           ┃
        // // ┗━━━━━━━━━━━┻━━━━━━━━━━━┻━━━━━━━━━━━━━╋━━━━━━━━━━━━━╋━━━━━━━━━━━━━╋━━━━━━━━━━━┫        ┣━━━━━━━━━━━╋━━━━━━━━━━━╋━━━━━━━━━━━╋━━━━━━━━━━━┻━━━━━━━━━━━┻━━━━━━━━━━━┛
        // //                                       ┃             ┃             ┃           ┃        ┃           ┃           ┃           ┃
        // //                                       ┗━━━━━━━━━━━━━┻━━━━━━━━━━━━━┻━━━━━━━━━━━┛        ┗━━━━━━━━━━━┻━━━━━━━━━━━┻━━━━━━━━━━━┛
        //  bindings = <
        // // ╷           ╷           ╷             ╷             ╷             ╷           ╷        ╷           ╷           ╷           ╷           ╷           ╷           ╷
        //                 &trans      &kp C_MUTE    &kp C_VOL_DN  &kp C_VOL_UP  &trans               &kp F12     &kp F7      &kp F8      &kp F9      &trans
        //                 &kp LGUI    &kp LSHFT     &kp LALT      &kp LCTRL     &trans               &kp F11     &kp F4      &kp F5      &kp F6      &trans
        //     &to BASE    &trans      &trans        &trans        &trans        &tog FUN             &kp F10     &kp F1      &kp F2      &kp F3      &trans      &trans
        //                                           &trans        &trans        &trans               &trans      &trans      &trans
        //                         >;
        //                 };
        // // ▄▄▄▄▄▄▄▄▄▄▄▄▄▄▄▄▄▄▄▄▄▄▄▄▄▄▄▄▄▄▄▄▄▄▄▄▄▄▄▄▄▄▄▄▄▄▄▄▄▄▄▄▄▄▄▄▄▄▄▄▄▄▄▄▄▄▄▄▄▄▄▄▄▄▄▄▄▄▄▄▄▄▄▄▄▄▄▄▄▄▄▄▄▄▄▄▄▄▄▄▄▄▄▄▄▄▄▄▄▄▄▄▄▄▄▄▄▄▄▄▄▄▄▄▄▄▄▄▄▄▄▄▄▄▄▄▄▄▄▄▄▄▄▄▄▄▄▄▄
        //                 macros_layer {
        // // ┏━━━━━━━━━━━━━━━━━━━━━━━━━━━━━━━━━━━━━━━┓
        // display-name= "MCR"                        ;
        // // ┗━━━━━━━━━━━━━━━━━━━━━━━━━━━━━━━━━━━━━━━┛
        // //             ┏━━━━━━━━━━━┳━━━━━━━━━━━┳━━━━━━━━━━━━━┳━━━━━━━━━━━┳━━━━━━━━━━━┓   ┏━━━━━━━━━━━┳━━━━━━━━━━━┳━━━━━━━━━━━━━━┳━━━━━━━━━━━┳━━━━━━━━━━━┓
        // //             ┃           ┃           ┃             ┃           ┃   SAVE    ┃   ┃           ┃  neovim   ┃   vimQuit    ┃           ┃           ┃
        // //             ┣━━━━━━━━━━━╋━━━━━━━━━━━╋━━━━━━━━━━━━━╋━━━━━━━━━━━╋━━━━━━━━━━━┫   ┣━━━━━━━━━━━╋━━━━━━━━━━━╋━━━━━━━━━━━━━━╋━━━━━━━━━━━╋━━━━━━━━━━━┫
        // //             ┃           ┃ PREV_HUNK ┃ Preview     ┃ NEXT_HUNK ┃  CMD+TAB  ┃   ┃    zfs    ┃  vimSave  ┃vimInsertSave ┃           ┃ exit + ↩  ┃
        // // ┏━━━━━━━━━━━╋━━━━━━━━━━━╋━━━━━━━━━━━╋━━━━━━━━━━━━━╋━━━━━━━━━━━╋━━━━━━━━━━━┫   ┣━━━━━━━━━━━╋━━━━━━━━━━━╋━━━━━━━━━━━━━━╋━━━━━━━━━━━╋━━━━━━━━━━━╋━━━━━━━━━━━┓
        // // ┃ TO BASE   ┃           ┃ PREV_DIAG ┃             ┃ NEXT_DIAG ┃           ┃   ┃vimSaveQuit┃git status ┃              ┃           ┃           ┃ nvim Term ┃
        // // ┗━━━━━━━━━━━┻━━━━━━━━━━━┻━━━━━━━━━━━╋━━━━━━━━━━━━━╋━━━━━━━━━━━╋━━━━━━━━━━━┫   ┣━━━━━━━━━━━╋━━━━━━━━━━━╋━━━━━━━━━━━━━━╋━━━━━━━━━━━┻━━━━━━━━━━━┻━━━━━━━━━━━┛
        // //                                     ┃             ┃           ┃           ┃   ┃           ┃           ┃              ┃
        // //                                     ┗━━━━━━━━━━━━━┻━━━━━━━━━━━┻━━━━━━━━━━━┛   ┗━━━━━━━━━━━┻━━━━━━━━━━━┻━━━━━━━━━━━━━━┛
        //  bindings = <
        // // ╷           ╷           ╷           ╷             ╷           ╷           ╷   ╷           ╷           ╷              ╷           ╷           ╷           ╷
        //                 &trans      &trans      &trans        &trans      &kp LG(S)       &trans      &nvim       &nvimqt        &trans      &trans
        //                 &trans      &prevhunk   &preview_hunk &nexthunk   &appswmac       &zfs        &visave     &vinsertsave   &trans      &texit
        //     &to BASE    &trans      &prevdiag   &trans        &nextdiag   &trans          &viquit     &gitstat    &trans         &trans      &trans       &nvimt
        //                                         &trans        &trans      &trans          &trans      &trans      &trans
        //                         >;
        //                 };
        // // ▄▄▄▄▄▄▄▄▄▄▄▄▄▄▄▄▄▄▄▄▄▄▄▄▄▄▄▄▄▄▄▄▄▄▄▄▄▄▄▄▄▄▄▄▄▄▄▄▄▄▄▄▄▄▄▄▄▄▄▄▄▄▄▄▄▄▄▄▄▄▄▄▄▄▄▄▄▄▄▄▄▄▄▄▄▄▄▄▄▄▄▄▄▄▄▄▄▄▄▄▄▄▄▄▄▄▄▄▄▄▄▄▄▄▄▄▄▄▄▄▄▄▄▄▄▄▄▄▄▄▄▄▄▄▄▄▄▄▄▄▄▄▄▄▄▄▄▄▄
        //                 system_layer {
        // // ┏━━━━━━━━━━━━━━━━━━━━━━━━━━━━━━━━━━━━━━━┓
        // display-name= "SYS"                        ;
        // // ┗━━━━━━━━━━━━━━━━━━━━━━━━━━━━━━━━━━━━━━━┛
        // //             ┏━━━━━━━━━━━┳━━━━━━━━━━━━━┳━━━━━━━━━━━━┳━━━━━━━━━━━┳━━━━━━━━━━━┓      ┏━━━━━━━━━━━┳━━━━━━━━━━━┳━━━━━━━━━━━┳━━━━━━━━━━━┳━━━━━━━━━━━┓
        // //             ┃           ┃TOGGLE OUT   ┃ BT_CLR     ┃ OUT USB   ┃     {     ┃      ┃           ┃           ┃           ┃           ┃  TOG SYS  ┃
        // //             ┣━━━━━━━━━━━╋━━━━━━━━━━━━━╋━━━━━━━━━━━━╋━━━━━━━━━━━╋━━━━━━━━━━━┫      ┣━━━━━━━━━━━╋━━━━━━━━━━━╋━━━━━━━━━━━╋━━━━━━━━━━━╋━━━━━━━━━━━┫
        // //             ┃ BT_SEL0   ┃ BT_SEL1     ┃ BT_SEL2    ┃ BT_SEL3   ┃     [     ┃      ┃           ┃           ┃           ┃           ┃           ┃
        // // ┏━━━━━━━━━━━╋━━━━━━━━━━━╋━━━━━━━━━━━━━╋━━━━━━━━━━━━╋━━━━━━━━━━━╋━━━━━━━━━━━┫      ┣━━━━━━━━━━━╋━━━━━━━━━━━╋━━━━━━━━━━━╋━━━━━━━━━━━╋━━━━━━━━━━━╋━━━━━━━━━━━┓
        // // ┃ TO BASE   ┃bootloader ┃ RESET       ┃            ┃  BT_CLR   ┃BT_CLR_ALL ┃      ┃BT_CLR_ALL ┃           ┃           ┃ RESET     ┃bootloader ┃           ┃
        // // ┗━━━━━━━━━━━┻━━━━━━━━━━━┻━━━━━━━━━━━━━╋━━━━━━━━━━━━╋━━━━━━━━━━━╋━━━━━━━━━━━┫      ┣━━━━━━━━━━━╋━━━━━━━━━━━╋━━━━━━━━━━━╋━━━━━━━━━━━┻━━━━━━━━━━━┻━━━━━━━━━━━┛
        // //                                       ┃            ┃           ┃           ┃      ┃           ┃           ┃           ┃
        // //                                       ┗━━━━━━━━━━━━┻━━━━━━━━━━━┻━━━━━━━━━━━┛      ┗━━━━━━━━━━━┻━━━━━━━━━━━┻━━━━━━━━━━━┛
        //  bindings = <
        // // ╷           ╷           ╷             ╷            ╷           ╷           ╷      ╷           ╷           ╷           ╷           ╷           ╷           ╷
        //                 &trans      &out OUT_TOG &bt BT_CLR   &out OUT_USB &kp LBRC           &trans      &trans      &trans      &trans      &tog SYS
        //                 &bt_0       &bt_1        &bt_2        &bt_3        &kp LBKT           &trans      &trans      &trans      &trans      &trans
        //     &to BASE    &bootloader &sys_reset   &trans       &bt BT_CLR   &bt_clrall         &bt_clrall  &trans      &trans      &sys_reset  &bootloader &trans
        //                                          &trans       &trans       &trans             &trans      &trans      &trans
        //                         >;
        //                 };
        // // ▄▄▄▄▄▄▄▄▄▄▄▄▄▄▄▄▄▄▄▄▄▄▄▄▄▄▄▄▄▄▄▄▄▄▄▄▄▄▄▄▄▄▄▄▄▄▄▄▄▄▄▄▄▄▄▄▄▄▄▄▄▄▄▄▄▄▄▄▄▄▄▄▄▄▄▄▄▄▄▄▄▄▄▄▄▄▄▄▄▄▄▄▄▄▄▄▄▄▄▄▄▄▄▄▄▄▄▄▄▄▄▄▄▄▄▄▄▄▄▄▄▄▄▄▄▄▄▄▄▄▄▄▄▄▄▄▄▄▄▄▄▄▄▄▄▄▄▄▄
        //               shortcuts_layer {
        // // ┏━━━━━━━━━━━━━━━━━━━━━━━━━━━━━━━━━━━━━━━┓
        // display-name= "COMMON_SHORTCUTS"           ;
        // // ┗━━━━━━━━━━━━━━━━━━━━━━━━━━━━━━━━━━━━━━━┛
        // //             ┏━━━━━━━━━━━┳━━━━━━━━━━━┳━━━━━━━━━━━┳━━━━━━━━━━━┳━━━━━━━━━━━━┓    ┏━━━━━━━━━━━┳━━━━━━━━━━━┳━━━━━━━━━━━┳━━━━━━━━━━━┳━━━━━━━━━━━┓
        // //             ┃           ┃           ┃   CMD+R   ┃           ┃            ┃    ┃           ┃           ┃           ┃           ┃           ┃
        // //             ┣━━━━━━━━━━━╋━━━━━━━━━━━╋━━━━━━━━━━━╋━━━━━━━━━━━╋━━━━━━━━━━━━┫    ┣━━━━━━━━━━━╋━━━━━━━━━━━╋━━━━━━━━━━━╋━━━━━━━━━━━╋━━━━━━━━━━━┫
        // //             ┃           ┃   CMD+H   ┃   CMD+P   ┃   CMD+N   ┃    CMD+O   ┃    ┃           ┃           ┃           ┃           ┃           ┃
        // // ┏━━━━━━━━━━━╋━━━━━━━━━━━╋━━━━━━━━━━━╋━━━━━━━━━━━╋━━━━━━━━━━━╋━━━━━━━━━━━━┫    ┣━━━━━━━━━━━╋━━━━━━━━━━━╋━━━━━━━━━━━╋━━━━━━━━━━━╋━━━━━━━━━━━╋━━━━━━━━━━━┓
        // // ┃           ┃           ┃           ┃           ┃           ┃            ┃    ┃           ┃           ┃           ┃           ┃           ┃  TO BASE  ┃
        // // ┗━━━━━━━━━━━┻━━━━━━━━━━━┻━━━━━━━━━━━╋━━━━━━━━━━━╋━━━━━━━━━━━╋━━━━━━━━━━━━┫    ┣━━━━━━━━━━━╋━━━━━━━━━━━╋━━━━━━━━━━━╋━━━━━━━━━━━┻━━━━━━━━━━━┻━━━━━━━━━━━┛
        // //                                     ┃           ┃           ┃            ┃    ┃           ┃           ┃           ┃
        // //                                     ┗━━━━━━━━━━━┻━━━━━━━━━━━┻━━━━━━━━━━━━┛    ┗━━━━━━━━━━━┻━━━━━━━━━━━┻━━━━━━━━━━━┛
        //  bindings = <
        // // ╷           ╷           ╷           ╷           ╷           ╷            ╷    ╷           ╷           ╷           ╷           ╷           ╷           ╷
        //                 &trans      &trans      &kp LG(R)   &trans      &trans            &trans      &trans      &trans      &trans      &trans
        //                 &trans      &kp LG(H)   &kp LG(P)   &kp LG(N)   &kp LG(O)         &trans      &trans      &trans      &trans      &trans
        //     &trans      &trans      &trans      &trans      &trans      &trans            &trans      &trans      &trans      &trans      &trans      &to BASE
        //                                         &trans      &trans      &trans            &trans      &trans      &trans
        //                         >;
        //                 };
        // // ▄▄▄▄▄▄▄▄▄▄▄▄▄▄▄▄▄▄▄▄▄▄▄▄▄▄▄▄▄▄▄▄▄▄▄▄▄▄▄▄▄▄▄▄▄▄▄▄▄▄▄▄▄▄▄▄▄▄▄▄▄▄▄▄▄▄▄▄▄▄▄▄▄▄▄▄▄▄▄▄▄▄▄▄▄▄▄▄▄▄▄▄▄▄▄▄▄▄▄▄▄▄▄▄▄▄▄▄▄▄▄▄▄▄▄▄▄▄▄▄▄▄▄▄▄▄▄▄▄▄▄▄▄▄▄▄▄▄▄▄▄▄▄▄▄▄▄▄▄
        //                 then_numbers_layer {
        // // ┏━━━━━━━━━━━━━━━━━━━━━━━━━━━━━━━━━━━━━━━┓
        // display-name= "THENWIN_NUM"                ;
        // // ┗━━━━━━━━━━━━━━━━━━━━━━━━━━━━━━━━━━━━━━━┛
        // //             ┏━━━━━━━━━━━┳━━━━━━━━━━━┳━━━━━━━━━━━┳━━━━━━━━━━━┳━━━━━━━━━━━━━━┓    ┏━━━━━━━━━━━┳━━━━━━━━━━━┳━━━━━━━━━━━┳━━━━━━━━━━━┳━━━━━━━━━━━┓
        // //             ┃           ┃           ┃           ┃           ┃     SAVE     ┃    ┃           ┃           ┃           ┃           ┃           ┃
        // //             ┣━━━━━━━━━━━╋━━━━━━━━━━━╋━━━━━━━━━━━╋━━━━━━━━━━━╋━━━━━━━━━━━━━━┫    ┣━━━━━━━━━━━╋━━━━━━━━━━━╋━━━━━━━━━━━╋━━━━━━━━━━━╋━━━━━━━━━━━┫
        // //             ┃           ┃           ┃           ┃           ┃    ALT+TAB   ┃    ┃           ┃           ┃           ┃           ┃           ┃
        // // ┏━━━━━━━━━━━╋━━━━━━━━━━━╋━━━━━━━━━━━╋━━━━━━━━━━━╋━━━━━━━━━━━╋━━━━━━━━━━━━━━┫    ┣━━━━━━━━━━━╋━━━━━━━━━━━╋━━━━━━━━━━━╋━━━━━━━━━━━╋━━━━━━━━━━━╋━━━━━━━━━━━┓
        // // ┃  TO BASE  ┃   UNDO    ┃    CUT    ┃    COPY   ┃   PASTE   ┃     REDO     ┃    ┃           ┃           ┃           ┃           ┃           ┃           ┃
        // // ┗━━━━━━━━━━━┻━━━━━━━━━━━┻━━━━━━━━━━━╋━━━━━━━━━━━╋━━━━━━━━━━━╋━━━━━━━━━━━━━━┫    ┣━━━━━━━━━━━╋━━━━━━━━━━━╋━━━━━━━━━━━╋━━━━━━━━━━━┻━━━━━━━━━━━┻━━━━━━━━━━━┛
        // //                                     ┃           ┃           ┃    CTRL+O    ┃    ┃           ┃           ┃           ┃
        // //                                     ┗━━━━━━━━━━━┻━━━━━━━━━━━┻━━━━━━━━━━━━━━┛    ┗━━━━━━━━━━━┻━━━━━━━━━━━┻━━━━━━━━━━━┛
        //  bindings = <
        // // ╷           ╷           ╷           ╷           ╷           ╷              ╷    ╷           ╷           ╷           ╷           ╷           ╷           ╷
        //                 &trans      &trans      &trans      &trans      &kp LC(S)           &trans      &trans      &trans      &trans      &trans
        //                 &trans      &trans      &trans      &trans      &appswwin           &trans      &trans      &trans      &trans      &trans
        //     &to BASE    &kp LC(Z)   &kp LC(X)   &kp LC(C)   &kp LC(V)   &kp LS(LC(Z))       &trans      &trans      &trans      &trans      &trans      &trans
        //                                         &trans      &trans      &kp LC(O)           &trans      &trans      &trans
        //                         >;
        //                 };
        // // ▄▄▄▄▄▄▄▄▄▄▄▄▄▄▄▄▄▄▄▄▄▄▄▄▄▄▄▄▄▄▄▄▄▄▄▄▄▄▄▄▄▄▄▄▄▄▄▄▄▄▄▄▄▄▄▄▄▄▄▄▄▄▄▄▄▄▄▄▄▄▄▄▄▄▄▄▄▄▄▄▄▄▄▄▄▄▄▄▄▄▄▄▄▄▄▄▄▄▄▄▄▄▄▄▄▄▄▄▄▄▄▄▄▄▄▄▄▄▄▄▄▄▄▄▄▄▄▄▄▄▄▄▄▄▄▄▄▄▄▄▄▄▄▄▄▄▄▄▄
        //                 then_cursor_layer {
        // // ┏━━━━━━━━━━━━━━━━━━━━━━━━━━━━━━━━━━━━━━━┓
        // display-name= "THENWIN_CUR"                ;
        // // ┗━━━━━━━━━━━━━━━━━━━━━━━━━━━━━━━━━━━━━━━┛
        // //             ┏━━━━━━━━━━━┳━━━━━━━━━━━┳━━━━━━━━━━━┳━━━━━━━━━━━┳━━━━━━━━━━━━━━┓     ┏━━━━━━━━━━━┳━━━━━━━━━━━┳━━━━━━━━━━━┳━━━━━━━━━━┳━━━━━━━━━━━┓
        // //             ┃           ┃           ┃           ┃           ┃     SAVE     ┃     ┃           ┃           ┃           ┃          ┃           ┃
        // //             ┣━━━━━━━━━━━╋━━━━━━━━━━━╋━━━━━━━━━━━╋━━━━━━━━━━━╋━━━━━━━━━━━━━━┫     ┣━━━━━━━━━━━╋━━━━━━━━━━━╋━━━━━━━━━━━╋━━━━━━━━━━╋━━━━━━━━━━━┫
        // //             ┃           ┃           ┃           ┃           ┃    ALT+TAB   ┃     ┃    Home   ┃           ┃           ┃          ┃   End     ┃
        // // ┏━━━━━━━━━━━╋━━━━━━━━━━━╋━━━━━━━━━━━╋━━━━━━━━━━━╋━━━━━━━━━━━╋━━━━━━━━━━━━━━┫     ┣━━━━━━━━━━━╋━━━━━━━━━━━╋━━━━━━━━━━━╋━━━━━━━━━━╋━━━━━━━━━━━╋━━━━━━━━━━━┓
        // // ┃  TO BASE  ┃   UNDO    ┃    CUT    ┃    COPY   ┃   PASTE   ┃     REDO     ┃     ┃           ┃           ┃           ┃          ┃           ┃           ┃
        // // ┗━━━━━━━━━━━┻━━━━━━━━━━━┻━━━━━━━━━━━╋━━━━━━━━━━━╋━━━━━━━━━━━╋━━━━━━━━━━━━━━┫     ┣━━━━━━━━━━━╋━━━━━━━━━━━╋━━━━━━━━━━━╋━━━━━━━━━━┻━━━━━━━━━━━┻━━━━━━━━━━━┛
        // //                                     ┃           ┃           ┃              ┃     ┃           ┃           ┃           ┃
        // //                                     ┗━━━━━━━━━━━┻━━━━━━━━━━━┻━━━━━━━━━━━━━━┛     ┗━━━━━━━━━━━┻━━━━━━━━━━━┻━━━━━━━━━━━┛
        //  bindings = <
        // // ╷           ╷           ╷           ╷           ╷           ╷              ╷     ╷           ╷           ╷           ╷          ╷           ╷           ╷
        //                 &trans      &trans      &trans      &trans      &kp LC(S)            &trans      &trans      &trans      &trans     &trans
        //                 &trans      &trans      &trans      &trans      &appswwin            &kp HOME    &trans      &trans      &trans     &kp END
        //     &to BASE    &kp LC(Z)   &kp LC(X)   &kp LC(C)   &kp LC(V)   &kp LS(LC(Z))        &trans      &trans      &trans      &trans     &trans      &trans
        //                                         &trans      &trans      &trans               &trans      &trans      &trans
        //                         >;
        //                 };
        // // ▄▄▄▄▄▄▄▄▄▄▄▄▄▄▄▄▄▄▄▄▄▄▄▄▄▄▄▄▄▄▄▄▄▄▄▄▄▄▄▄▄▄▄▄▄▄▄▄▄▄▄▄▄▄▄▄▄▄▄▄▄▄▄▄▄▄▄▄▄▄▄▄▄▄▄▄▄▄▄▄▄▄▄▄▄▄▄▄▄▄▄▄▄▄▄▄▄▄▄▄▄▄▄▄▄▄▄▄▄▄▄▄▄▄▄▄▄▄▄▄▄▄▄▄▄▄▄▄▄▄▄▄▄▄▄▄▄▄▄▄▄▄▄▄▄▄▄▄▄
        //                 then_macros_layer {
        // // ┏━━━━━━━━━━━━━━━━━━━━━━━━━━━━━━━━━━━━━━━┓
        // display-name= "THENWIN_MCR"                ;
        // // ┗━━━━━━━━━━━━━━━━━━━━━━━━━━━━━━━━━━━━━━━┛
        // //             ┏━━━━━━━━━━━┳━━━━━━━━━━━┳━━━━━━━━━━━┳━━━━━━━━━━━┳━━━━━━━━━━━┓    ┏━━━━━━━━━━━┳━━━━━━━━━━━┳━━━━━━━━━━━┳━━━━━━━━━━━┳━━━━━━━━━━━┓
        // //             ┃           ┃           ┃           ┃           ┃   SAVE    ┃    ┃           ┃           ┃           ┃           ┃           ┃
        // //             ┣━━━━━━━━━━━╋━━━━━━━━━━━╋━━━━━━━━━━━╋━━━━━━━━━━━╋━━━━━━━━━━━┫    ┣━━━━━━━━━━━╋━━━━━━━━━━━╋━━━━━━━━━━━╋━━━━━━━━━━━╋━━━━━━━━━━━┫
        // //             ┃           ┃           ┃           ┃           ┃  ALT+TAB  ┃    ┃           ┃           ┃           ┃           ┃           ┃
        // // ┏━━━━━━━━━━━╋━━━━━━━━━━━╋━━━━━━━━━━━╋━━━━━━━━━━━╋━━━━━━━━━━━╋━━━━━━━━━━━┫    ┣━━━━━━━━━━━╋━━━━━━━━━━━╋━━━━━━━━━━━╋━━━━━━━━━━━╋━━━━━━━━━━━╋━━━━━━━━━━━┓
        // // ┃  TO BASE  ┃           ┃           ┃           ┃           ┃           ┃    ┃           ┃           ┃           ┃           ┃           ┃           ┃
        // // ┗━━━━━━━━━━━┻━━━━━━━━━━━┻━━━━━━━━━━━╋━━━━━━━━━━━╋━━━━━━━━━━━╋━━━━━━━━━━━┫    ┣━━━━━━━━━━━╋━━━━━━━━━━━╋━━━━━━━━━━━╋━━━━━━━━━━━┻━━━━━━━━━━━┻━━━━━━━━━━━┛
        // //                                     ┃           ┃           ┃           ┃    ┃           ┃           ┃           ┃
        // //                                     ┗━━━━━━━━━━━┻━━━━━━━━━━━┻━━━━━━━━━━━┛    ┗━━━━━━━━━━━┻━━━━━━━━━━━┻━━━━━━━━━━━┛
        //  bindings = <
        // // ╷           ╷           ╷           ╷           ╷           ╷           ╷    ╷           ╷           ╷           ╷           ╷           ╷           ╷
        //                 &trans      &trans      &trans      &trans      &kp LC(S)        &trans      &trans      &trans      &trans      &trans
        //                 &trans      &trans      &trans      &trans      &appswwin        &trans      &trans      &trans      &trans      &trans
        //     &to BASE    &trans      &trans      &trans      &trans      &trans           &trans      &trans      &trans      &trans      &trans      &trans
        //                                         &trans      &trans      &trans           &trans      &trans      &trans
        //                         >;
        //                 };
        // // ▄▄▄▄▄▄▄▄▄▄▄▄▄▄▄▄▄▄▄▄▄▄▄▄▄▄▄▄▄▄▄▄▄▄▄▄▄▄▄▄▄▄▄▄▄▄▄▄▄▄▄▄▄▄▄▄▄▄▄▄▄▄▄▄▄▄▄▄▄▄▄▄▄▄▄▄▄▄▄▄▄▄▄▄▄▄▄▄▄▄▄▄▄▄▄▄▄▄▄▄▄▄▄▄▄▄▄▄▄▄▄▄▄▄▄▄▄▄▄▄▄▄▄▄▄▄▄▄▄▄▄▄▄▄▄▄▄▄▄▄▄▄▄▄▄▄▄▄▄
        //               then_shortcuts_layer {
        // // ┏━━━━━━━━━━━━━━━━━━━━━━━━━━━━━━━━━━━━━━━┓
        // display-name= "THENWIN_SHORTCUTS"          ;
        // // ┗━━━━━━━━━━━━━━━━━━━━━━━━━━━━━━━━━━━━━━━┛
        // //             ┏━━━━━━━━━━━┳━━━━━━━━━━━┳━━━━━━━━━━━┳━━━━━━━━━━━┳━━━━━━━━━━━━┓    ┏━━━━━━━━━━━┳━━━━━━━━━━━┳━━━━━━━━━━━┳━━━━━━━━━━━┳━━━━━━━━━━━┓
        // //             ┃           ┃           ┃   CTRL+R  ┃           ┃            ┃    ┃           ┃           ┃           ┃           ┃           ┃
        // //             ┣━━━━━━━━━━━╋━━━━━━━━━━━╋━━━━━━━━━━━╋━━━━━━━━━━━╋━━━━━━━━━━━━┫    ┣━━━━━━━━━━━╋━━━━━━━━━━━╋━━━━━━━━━━━╋━━━━━━━━━━━╋━━━━━━━━━━━┫
        // //             ┃           ┃  CTRL+H   ┃   CTRL+P  ┃  CTRL+N   ┃   CTRL+O   ┃    ┃           ┃           ┃           ┃           ┃           ┃
        // // ┏━━━━━━━━━━━╋━━━━━━━━━━━╋━━━━━━━━━━━╋━━━━━━━━━━━╋━━━━━━━━━━━╋━━━━━━━━━━━━┫    ┣━━━━━━━━━━━╋━━━━━━━━━━━╋━━━━━━━━━━━╋━━━━━━━━━━━╋━━━━━━━━━━━╋━━━━━━━━━━━┓
        // // ┃           ┃           ┃           ┃           ┃           ┃            ┃    ┃           ┃           ┃           ┃           ┃           ┃  TO BASE  ┃
        // // ┗━━━━━━━━━━━┻━━━━━━━━━━━┻━━━━━━━━━━━╋━━━━━━━━━━━╋━━━━━━━━━━━╋━━━━━━━━━━━━┫    ┣━━━━━━━━━━━╋━━━━━━━━━━━╋━━━━━━━━━━━╋━━━━━━━━━━━┻━━━━━━━━━━━┻━━━━━━━━━━━┛
        // //                                     ┃           ┃           ┃            ┃    ┃           ┃           ┃           ┃
        // //                                     ┗━━━━━━━━━━━┻━━━━━━━━━━━┻━━━━━━━━━━━━┛    ┗━━━━━━━━━━━┻━━━━━━━━━━━┻━━━━━━━━━━━┛
        //  bindings = <
        // // ╷           ╷           ╷           ╷           ╷           ╷            ╷    ╷           ╷           ╷           ╷           ╷           ╷           ╷
        //                 &trans      &trans      &kp LC(R)   &trans      &trans            &trans      &trans      &trans      &trans      &trans
        //                 &trans      &kp LC(H)   &kp LC(P)   &kp LC(N)   &kp LC(O)         &trans      &trans      &trans      &trans      &trans
        //     &trans      &trans      &trans      &trans      &trans      &trans            &trans      &trans      &trans      &trans      &trans      &to BASE
        //                                         &trans      &trans      &trans            &trans      &trans      &trans
        //                         >;
        //                 };
        // ▄▄▄▄▄▄▄▄▄▄▄▄▄▄▄▄▄▄▄▄▄▄▄▄▄▄▄▄▄▄▄▄▄▄▄▄▄▄▄▄▄▄▄▄▄▄▄▄▄▄▄▄▄▄▄▄▄▄▄▄▄▄▄▄▄▄▄▄▄▄▄▄▄▄▄▄▄▄▄▄▄▄▄▄▄▄▄▄▄▄▄▄▄▄▄▄▄▄▄▄▄▄▄▄▄▄▄▄▄▄▄▄▄▄▄▄▄▄▄▄▄▄▄▄▄▄▄▄▄▄▄▄▄▄▄▄▄▄▄▄▄▄▄▄▄▄▄▄▄
        // tvp1_layer {
        // // ┏━━━━━━━━━━━━━━━━━━━━━━━━━━━━━━━━━━━━━━━┓
        // label= "TVP 1"                             ;
        // // ┗━━━━━━━━━━━━━━━━━━━━━━━━━━━━━━━━━━━━━━━┛
        // //             ┏━━━━━━━━━━━┳━━━━━━━━━━━┳━━━━━━━━━━━┳━━━━━━━━━━━┳━━━━━━━━━━━┓   ┏━━━━━━━━━━━┳━━━━━━━━━━━┳━━━━━━━━━━━┳━━━━━━━━━━━┳━━━━━━━━━━━┓
        // //             ┃ NEXT FILE ┃ MARK IN   ┃ ROTATE    ┃ MARK OUT  ┃ SHOW SNAP ┃   ┃           ┃           ┃           ┃           ┃           ┃
        // //             ┣━━━━━━━━━━━╋━━━━━━━━━━━╋━━━━━━━━━━━╋━━━━━━━━━━━╋━━━━━━━━━━━┫   ┣━━━━━━━━━━━╋━━━━━━━━━━━╋━━━━━━━━━━━╋━━━━━━━━━━━╋━━━━━━━━━━━┫
        // //             ┃ TVP II    ┃ LEFT      ┃ PAN       ┃ RIGHT     ┃ PLAY/FLIP ┃   ┃           ┃           ┃           ┃           ┃           ┃
        // // ┏━━━━━━━━━━━╋━━━━━━━━━━━╋━━━━━━━━━━━╋━━━━━━━━━━━╋━━━━━━━━━━━╋━━━━━━━━━━━┫   ┣━━━━━━━━━━━╋━━━━━━━━━━━╋━━━━━━━━━━━╋━━━━━━━━━━━╋━━━━━━━━━━━╋━━━━━━━━━━━┓
        // // ┃ FULLSCR   ┃ SHIFT     ┃ COPY      ┃ DELETE    ┃ PASTE     ┃ IMG MARK  ┃   ┃           ┃           ┃           ┃           ┃           ┃           ┃
        // // ┗━━━━━━━━━━━┻━━━━━━━━━━━┻━━━━━━━━━━━╋━━━━━━━━━━━╋━━━━━━━━━━━╋━━━━━━━━━━━┫   ┣━━━━━━━━━━━╋━━━━━━━━━━━╋━━━━━━━━━━━╋━━━━━━━━━━━┻━━━━━━━━━━━┻━━━━━━━━━━━┛
        // //                                     ┃           ┃ UNDO/SAVE ┃  SEL/MOV  ┃   ┃           ┃           ┃           ┃
        // //                                     ┗━━━━━━━━━━━┻━━━━━━━━━━━┻━━━━━━━━━━━┛   ┗━━━━━━━━━━━┻━━━━━━━━━━━┻━━━━━━━━━━━┛
        // bindings = <
        // // ╷           ╷           ╷           ╷           ╷           ╷           ╷   ╷           ╷           ╷           ╷           ╷           ╷           ╷
        // &kp TAB     &kp I       &kp LC(LALT) &kp O      &kp LC(F20)     &trans       &trans       &trans       &trans       &trans
        // &lt CUR L   &kp LEFT    &kp LALT    &kp RIGHT   &kp SPACE       &trans       &trans       &trans       &trans       &trans
        // &kp J       &kp LSHFT   &kp LC(C)   &kp BSPC    &kp LC(V)   &kp LC(F19)     &trans       &trans       &trans       &trans       &trans       &trans
        //                         &trans      &kp LC(F14) &kp LC(F13)     &trans       &trans       &trans
        //         >;
        // };
        // // ▄▄▄▄▄▄▄▄▄▄▄▄▄▄▄▄▄▄▄▄▄▄▄▄▄▄▄▄▄▄▄▄▄▄▄▄▄▄▄▄▄▄▄▄▄▄▄▄▄▄▄▄▄▄▄▄▄▄▄▄▄▄▄▄▄▄▄▄▄▄▄▄▄▄▄▄▄▄▄▄▄▄▄▄▄▄▄▄▄▄▄▄▄▄▄▄▄▄▄▄▄▄▄▄▄▄▄▄▄▄▄▄▄▄▄▄▄▄▄▄▄▄▄▄▄▄▄▄▄▄▄▄▄▄▄▄▄▄▄▄▄▄▄▄▄▄▄▄▄
        // tvp2_layer {
        // // ┏━━━━━━━━━━━━━━━━━━━━━━━━━━━━━━━━━━━━━━━┓
        // label= "TVP 2"                             ;
        // // ┗━━━━━━━━━━━━━━━━━━━━━━━━━━━━━━━━━━━━━━━┛
        // //             ┏━━━━━━━━━━━┳━━━━━━━━━━━┳━━━━━━━━━━━┳━━━━━━━━━━━┳━━━━━━━━━━━┓   ┏━━━━━━━━━━━┳━━━━━━━━━━━┳━━━━━━━━━━━┳━━━━━━━━━━━┳━━━━━━━━━━━┓
        // //             ┃ SOLO      ┃ TOGGLE IN ┃ RESET ROT ┃ TOGGLE OUT┃ TAKE SNAP ┃   ┃           ┃           ┃           ┃           ┃           ┃
        // //             ┣━━━━━━━━━━━╋━━━━━━━━━━━╋━━━━━━━━━━━╋━━━━━━━━━━━╋━━━━━━━━━━━┫   ┣━━━━━━━━━━━╋━━━━━━━━━━━╋━━━━━━━━━━━╋━━━━━━━━━━━╋━━━━━━━━━━━┫
        // //             ┃ ---       ┃ LAST KEY  ┃ NEW KEY   ┃ NEXT KEY  ┃ ENTER     ┃   ┃           ┃           ┃           ┃           ┃           ┃
        // // ┏━━━━━━━━━━━╋━━━━━━━━━━━╋━━━━━━━━━━━╋━━━━━━━━━━━╋━━━━━━━━━━━╋━━━━━━━━━━━┫   ┣━━━━━━━━━━━╋━━━━━━━━━━━╋━━━━━━━━━━━╋━━━━━━━━━━━╋━━━━━━━━━━━╋━━━━━━━━━━━┓
        // // ┃           ┃ FULLSCR   ┃ CPY2BRUSH ┃ DEL HEAD  ┃ PSTinPLACE┃ BOOK MARK ┃   ┃           ┃           ┃           ┃           ┃           ┃           ┃
        // // ┗━━━━━━━━━━━┻━━━━━━━━━━━┻━━━━━━━━━━━╋━━━━━━━━━━━╋━━━━━━━━━━━╋━━━━━━━━━━━┫   ┣━━━━━━━━━━━╋━━━━━━━━━━━╋━━━━━━━━━━━╋━━━━━━━━━━━┻━━━━━━━━━━━┻━━━━━━━━━━━┛
        // //                                     ┃           ┃ REDO/SAV1 ┃TRANS/WARP ┃   ┃           ┃           ┃           ┃
        // //                                     ┗━━━━━━━━━━━┻━━━━━━━━━━━┻━━━━━━━━━━━┛   ┗━━━━━━━━━━━┻━━━━━━━━━━━┻━━━━━━━━━━━┛
        // bindings = <
        // // ╷           ╷           ╷           ╷           ╷           ╷           ╷   ╷           ╷           ╷           ╷           ╷           ╷           ╷
        // &kp LC(F18) &kp LS(I)  &kp LS(HOME) &kp LS(O)   &kp LS(F)       &trans      &kp F7      &kp F8      &kp F9      &kp F12
        // &trans      &kp LS(LEFT) &kp LC(F17) &kp LS(RIGHT) &kp RET      &trans      &kp F4      &kp F5      &kp F6      &kp F11
        // &trans      &kp J       &kp LS(C)   &kp LC(F16) &kp LS(V)   &kp LC(F15)     &trans      &kp F1      &kp F2      &kp F3      &kp F10     &trans
        //                         &trans      &kp LC(F12) &kp LC(F11)     &trans      &trans      &trans
        //         >;
        // };
    };

    conditional_layers {
        compatible = "zmk,conditional-layers";

        tri_win_num {
            if-layers = <2 5>;
            then-layer = <11>;
        };

        tri_win_cur {
            if-layers = <2 6>;
            then-layer = <12>;
        };

        tri_win_macro {
            if-layers = <2 8>;
            then-layer = <13>;
        };

        tri_win_shortcuts {
            if-layers = <2 10>;
            then-layer = <14>;
        };
    };
};
